AUTOSAR XML (schema 4-0-3)
package /MICROSAR_SWCS_DEV/NvM_swc/ComponentTypes
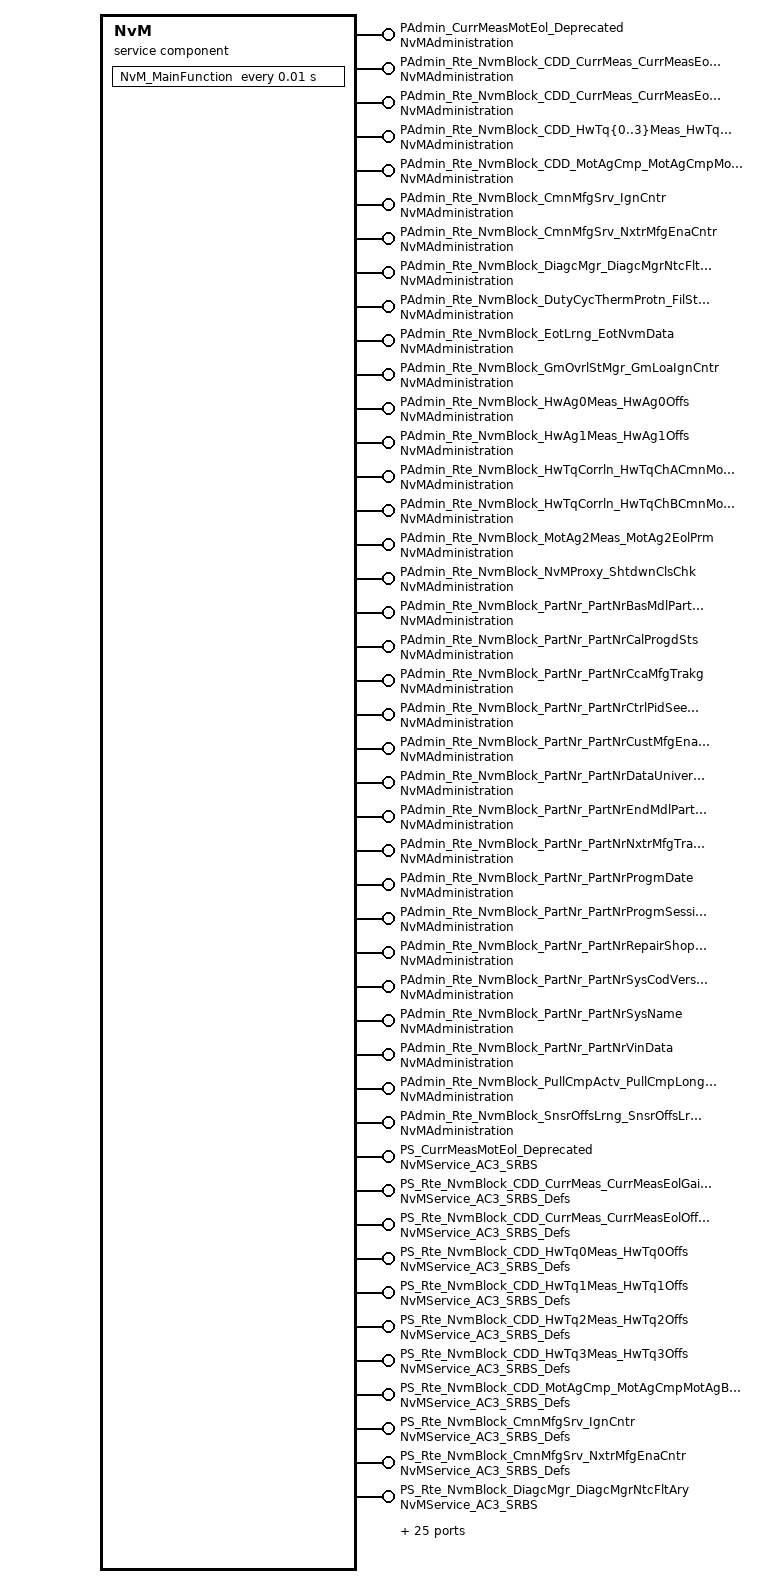
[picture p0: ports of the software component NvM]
  service sw component type NvM
    72 x provide port:
      PAdmin_CurrMeasMotEol_Deprecated: server-com-spec{operation=SetBlockProtection, queue-length=1}, provided-interface=NvMAdministration
      PAdmin_Rte_NvmBlock_CDD_CurrMeas_CurrMeasEolGainCalSet: server-com-spec{operation=SetBlockProtection, queue-length=1}, provided-interface=NvMAdministration
      PAdmin_Rte_NvmBlock_CDD_CurrMeas_CurrMeasEolOffsCalSet: server-com-spec{operation=SetBlockProtection, queue-length=1}, provided-interface=NvMAdministration
      PAdmin_Rte_NvmBlock_CDD_HwTq{0..3}Meas_HwTq{0..3}Offs: server-com-spec{operation=SetBlockProtection, queue-length=1}, provided-interface=NvMAdministration
      PAdmin_Rte_NvmBlock_CDD_MotAgCmp_MotAgCmpMotAgBackEmf: server-com-spec{operation=SetBlockProtection, queue-length=1}, provided-interface=NvMAdministration
      PAdmin_Rte_NvmBlock_CmnMfgSrv_IgnCntr: server-com-spec{operation=SetBlockProtection, queue-length=1}, provided-interface=NvMAdministration
      PAdmin_Rte_NvmBlock_CmnMfgSrv_NxtrMfgEnaCntr: server-com-spec{operation=SetBlockProtection, queue-length=1}, provided-interface=NvMAdministration
      PAdmin_Rte_NvmBlock_DiagcMgr_DiagcMgrNtcFltAry: server-com-spec{operation=SetBlockProtection, queue-length=1}, provided-interface=NvMAdministration
      PAdmin_Rte_NvmBlock_DutyCycThermProtn_FilStVal: server-com-spec{operation=SetBlockProtection, queue-length=1}, provided-interface=NvMAdministration
      PAdmin_Rte_NvmBlock_EotLrng_EotNvmData: server-com-spec{operation=SetBlockProtection, queue-length=1}, provided-interface=NvMAdministration
      PAdmin_Rte_NvmBlock_GmOvrlStMgr_GmLoaIgnCntr: server-com-spec{operation=SetBlockProtection, queue-length=1}, provided-interface=NvMAdministration
      PAdmin_Rte_NvmBlock_HwAg0Meas_HwAg0Offs: server-com-spec{operation=SetBlockProtection, queue-length=1}, provided-interface=NvMAdministration
      PAdmin_Rte_NvmBlock_HwAg1Meas_HwAg1Offs: server-com-spec{operation=SetBlockProtection, queue-length=1}, provided-interface=NvMAdministration
      PAdmin_Rte_NvmBlock_HwTqCorrln_HwTqChACmnModCmpLpFilSt: server-com-spec{operation=SetBlockProtection, queue-length=1}, provided-interface=NvMAdministration
      PAdmin_Rte_NvmBlock_HwTqCorrln_HwTqChBCmnModCmpLpFilSt: server-com-spec{operation=SetBlockProtection, queue-length=1}, provided-interface=NvMAdministration
      PAdmin_Rte_NvmBlock_MotAg2Meas_MotAg2EolPrm: server-com-spec{operation=SetBlockProtection, queue-length=1}, provided-interface=NvMAdministration
      PAdmin_Rte_NvmBlock_NvMProxy_ShtdwnClsChk: server-com-spec{operation=SetBlockProtection, queue-length=1}, provided-interface=NvMAdministration
      PAdmin_Rte_NvmBlock_PartNr_PartNrBasMdlPartNr: server-com-spec{operation=SetBlockProtection, queue-length=1}, provided-interface=NvMAdministration
      PAdmin_Rte_NvmBlock_PartNr_PartNrCalProgdSts: server-com-spec{operation=SetBlockProtection, queue-length=1}, provided-interface=NvMAdministration
      PAdmin_Rte_NvmBlock_PartNr_PartNrCcaMfgTrakg: server-com-spec{operation=SetBlockProtection, queue-length=1}, provided-interface=NvMAdministration
      PAdmin_Rte_NvmBlock_PartNr_PartNrCtrlPidSeedKey: server-com-spec{operation=SetBlockProtection, queue-length=1}, provided-interface=NvMAdministration
      PAdmin_Rte_NvmBlock_PartNr_PartNrCustMfgEnaCntr: server-com-spec{operation=SetBlockProtection, queue-length=1}, provided-interface=NvMAdministration
      PAdmin_Rte_NvmBlock_PartNr_PartNrDataUniversalNrSysId: server-com-spec{operation=SetBlockProtection, queue-length=1}, provided-interface=NvMAdministration
      PAdmin_Rte_NvmBlock_PartNr_PartNrEndMdlPartNr: server-com-spec{operation=SetBlockProtection, queue-length=1}, provided-interface=NvMAdministration
      PAdmin_Rte_NvmBlock_PartNr_PartNrNxtrMfgTrakg: server-com-spec{operation=SetBlockProtection, queue-length=1}, provided-interface=NvMAdministration
      PAdmin_Rte_NvmBlock_PartNr_PartNrProgmDate: server-com-spec{operation=SetBlockProtection, queue-length=1}, provided-interface=NvMAdministration
      PAdmin_Rte_NvmBlock_PartNr_PartNrProgmSessionSeedKey: server-com-spec{operation=SetBlockProtection, queue-length=1}, provided-interface=NvMAdministration
      PAdmin_Rte_NvmBlock_PartNr_PartNrRepairShopCod: server-com-spec{operation=SetBlockProtection, queue-length=1}, provided-interface=NvMAdministration
      PAdmin_Rte_NvmBlock_PartNr_PartNrSysCodVersNr: server-com-spec{operation=SetBlockProtection, queue-length=1}, provided-interface=NvMAdministration
      PAdmin_Rte_NvmBlock_PartNr_PartNrSysName: server-com-spec{operation=SetBlockProtection, queue-length=1}, provided-interface=NvMAdministration
      PAdmin_Rte_NvmBlock_PartNr_PartNrVinData: server-com-spec{operation=SetBlockProtection, queue-length=1}, provided-interface=NvMAdministration
      PAdmin_Rte_NvmBlock_PullCmpActv_PullCmpLongTerm: server-com-spec{operation=SetBlockProtection, queue-length=1}, provided-interface=NvMAdministration
      PAdmin_Rte_NvmBlock_SnsrOffsLrng_SnsrOffsLrnd: server-com-spec{operation=SetBlockProtection, queue-length=1}, provided-interface=NvMAdministration
      PS_CurrMeasMotEol_Deprecated: provided-interface=NvMService_AC3_SRBS
        provided-com-specs:
          operation=EraseBlock, queue-length=1
          operation=GetErrorStatus, queue-length=1
          operation=InvalidateNvBlock, queue-length=1
          operation=ReadBlock, queue-length=1
          operation=SetRamBlockStatus, queue-length=1
          operation=WriteBlock, queue-length=1
      PS_Rte_NvmBlock_CDD_CurrMeas_CurrMeasEolGainCalSet: provided-interface=NvMService_AC3_SRBS_Defs
        provided-com-specs:
          operation=EraseBlock, queue-length=1
          operation=GetErrorStatus, queue-length=1
          operation=InvalidateNvBlock, queue-length=1
          operation=ReadBlock, queue-length=1
          operation=RestoreBlockDefaults, queue-length=1
          operation=SetRamBlockStatus, queue-length=1
          operation=WriteBlock, queue-length=1
      PS_Rte_NvmBlock_CDD_CurrMeas_CurrMeasEolOffsCalSet: provided-interface=NvMService_AC3_SRBS_Defs
        provided-com-specs:
          operation=EraseBlock, queue-length=1
          operation=GetErrorStatus, queue-length=1
          operation=InvalidateNvBlock, queue-length=1
          operation=ReadBlock, queue-length=1
          operation=RestoreBlockDefaults, queue-length=1
          operation=SetRamBlockStatus, queue-length=1
          operation=WriteBlock, queue-length=1
      PS_Rte_NvmBlock_CDD_HwTq0Meas_HwTq0Offs: provided-interface=NvMService_AC3_SRBS_Defs
        provided-com-specs:
          operation=EraseBlock, queue-length=1
          operation=GetErrorStatus, queue-length=1
          operation=InvalidateNvBlock, queue-length=1
          operation=ReadBlock, queue-length=1
          operation=RestoreBlockDefaults, queue-length=1
          operation=SetRamBlockStatus, queue-length=1
          operation=WriteBlock, queue-length=1
      PS_Rte_NvmBlock_CDD_HwTq1Meas_HwTq1Offs: provided-interface=NvMService_AC3_SRBS_Defs
        provided-com-specs:
          operation=EraseBlock, queue-length=1
          operation=GetErrorStatus, queue-length=1
          operation=InvalidateNvBlock, queue-length=1
          operation=ReadBlock, queue-length=1
          operation=RestoreBlockDefaults, queue-length=1
          operation=SetRamBlockStatus, queue-length=1
          operation=WriteBlock, queue-length=1
      PS_Rte_NvmBlock_CDD_HwTq2Meas_HwTq2Offs: provided-interface=NvMService_AC3_SRBS_Defs
        provided-com-specs:
          operation=EraseBlock, queue-length=1
          operation=GetErrorStatus, queue-length=1
          operation=InvalidateNvBlock, queue-length=1
          operation=ReadBlock, queue-length=1
          operation=RestoreBlockDefaults, queue-length=1
          operation=SetRamBlockStatus, queue-length=1
          operation=WriteBlock, queue-length=1
      PS_Rte_NvmBlock_CDD_HwTq3Meas_HwTq3Offs: provided-interface=NvMService_AC3_SRBS_Defs
        provided-com-specs:
          operation=EraseBlock, queue-length=1
          operation=GetErrorStatus, queue-length=1
          operation=InvalidateNvBlock, queue-length=1
          operation=ReadBlock, queue-length=1
          operation=RestoreBlockDefaults, queue-length=1
          operation=SetRamBlockStatus, queue-length=1
          operation=WriteBlock, queue-length=1
      PS_Rte_NvmBlock_CDD_MotAgCmp_MotAgCmpMotAgBackEmf: provided-interface=NvMService_AC3_SRBS_Defs
        provided-com-specs:
          operation=EraseBlock, queue-length=1
          operation=GetErrorStatus, queue-length=1
          operation=InvalidateNvBlock, queue-length=1
          operation=ReadBlock, queue-length=1
          operation=RestoreBlockDefaults, queue-length=1
          operation=SetRamBlockStatus, queue-length=1
          operation=WriteBlock, queue-length=1
      PS_Rte_NvmBlock_CmnMfgSrv_IgnCntr: provided-interface=NvMService_AC3_SRBS_Defs
        provided-com-specs:
          operation=EraseBlock, queue-length=1
          operation=GetErrorStatus, queue-length=1
          operation=InvalidateNvBlock, queue-length=1
          operation=ReadBlock, queue-length=1
          operation=RestoreBlockDefaults, queue-length=1
          operation=SetRamBlockStatus, queue-length=1
          operation=WriteBlock, queue-length=1
      PS_Rte_NvmBlock_CmnMfgSrv_NxtrMfgEnaCntr: provided-interface=NvMService_AC3_SRBS_Defs
        provided-com-specs:
          operation=EraseBlock, queue-length=1
          operation=GetErrorStatus, queue-length=1
          operation=InvalidateNvBlock, queue-length=1
          operation=ReadBlock, queue-length=1
          operation=RestoreBlockDefaults, queue-length=1
          operation=SetRamBlockStatus, queue-length=1
          operation=WriteBlock, queue-length=1
      PS_Rte_NvmBlock_DiagcMgr_DiagcMgrNtcFltAry: provided-interface=NvMService_AC3_SRBS
        provided-com-specs:
          operation=EraseBlock, queue-length=1
          operation=GetErrorStatus, queue-length=1
          operation=InvalidateNvBlock, queue-length=1
          operation=ReadBlock, queue-length=1
          operation=SetRamBlockStatus, queue-length=1
          operation=WriteBlock, queue-length=1
      PS_Rte_NvmBlock_DutyCycThermProtn_FilStVal: provided-interface=NvMService_AC3_SRBS_Defs
        provided-com-specs:
          operation=EraseBlock, queue-length=1
          operation=GetErrorStatus, queue-length=1
          operation=InvalidateNvBlock, queue-length=1
          operation=ReadBlock, queue-length=1
          operation=RestoreBlockDefaults, queue-length=1
          operation=SetRamBlockStatus, queue-length=1
          operation=WriteBlock, queue-length=1
      PS_Rte_NvmBlock_EotLrng_EotNvmData: provided-interface=NvMService_AC3_SRBS_Defs
        provided-com-specs:
          operation=EraseBlock, queue-length=1
          operation=GetErrorStatus, queue-length=1
          operation=InvalidateNvBlock, queue-length=1
          operation=ReadBlock, queue-length=1
          operation=RestoreBlockDefaults, queue-length=1
          operation=SetRamBlockStatus, queue-length=1
          operation=WriteBlock, queue-length=1
      PS_Rte_NvmBlock_GmOvrlStMgr_GmLoaIgnCntr: provided-interface=NvMService_AC3_SRBS
        provided-com-specs:
          operation=EraseBlock, queue-length=1
          operation=GetErrorStatus, queue-length=1
          operation=InvalidateNvBlock, queue-length=1
          operation=ReadBlock, queue-length=1
          operation=SetRamBlockStatus, queue-length=1
          operation=WriteBlock, queue-length=1
      PS_Rte_NvmBlock_HwAg0Meas_HwAg0Offs: provided-interface=NvMService_AC3_SRBS_Defs
        provided-com-specs:
          operation=EraseBlock, queue-length=1
          operation=GetErrorStatus, queue-length=1
          operation=InvalidateNvBlock, queue-length=1
          operation=ReadBlock, queue-length=1
          operation=RestoreBlockDefaults, queue-length=1
          operation=SetRamBlockStatus, queue-length=1
          operation=WriteBlock, queue-length=1
      PS_Rte_NvmBlock_HwAg1Meas_HwAg1Offs: provided-interface=NvMService_AC3_SRBS_Defs
        provided-com-specs:
          operation=EraseBlock, queue-length=1
          operation=GetErrorStatus, queue-length=1
          operation=InvalidateNvBlock, queue-length=1
          operation=ReadBlock, queue-length=1
          operation=RestoreBlockDefaults, queue-length=1
          operation=SetRamBlockStatus, queue-length=1
          operation=WriteBlock, queue-length=1
      PS_Rte_NvmBlock_HwTqCorrln_HwTqChACmnModCmpLpFilSt: provided-interface=NvMService_AC3_SRBS_Defs
        provided-com-specs:
          operation=EraseBlock, queue-length=1
          operation=GetErrorStatus, queue-length=1
          operation=InvalidateNvBlock, queue-length=1
          operation=ReadBlock, queue-length=1
          operation=RestoreBlockDefaults, queue-length=1
          operation=SetRamBlockStatus, queue-length=1
          operation=WriteBlock, queue-length=1
      PS_Rte_NvmBlock_HwTqCorrln_HwTqChBCmnModCmpLpFilSt: provided-interface=NvMService_AC3_SRBS_Defs
        provided-com-specs:
          operation=EraseBlock, queue-length=1
          operation=GetErrorStatus, queue-length=1
          operation=InvalidateNvBlock, queue-length=1
          operation=ReadBlock, queue-length=1
          operation=RestoreBlockDefaults, queue-length=1
          operation=SetRamBlockStatus, queue-length=1
          operation=WriteBlock, queue-length=1
      PS_Rte_NvmBlock_MotAg2Meas_MotAg2EolPrm: provided-interface=NvMService_AC3_SRBS_Defs
        provided-com-specs:
          operation=EraseBlock, queue-length=1
          operation=GetErrorStatus, queue-length=1
          operation=InvalidateNvBlock, queue-length=1
          operation=ReadBlock, queue-length=1
          operation=RestoreBlockDefaults, queue-length=1
          operation=SetRamBlockStatus, queue-length=1
          operation=WriteBlock, queue-length=1
      PS_Rte_NvmBlock_NvMProxy_ShtdwnClsChk: provided-interface=NvMService_AC3_SRBS
        provided-com-specs:
          operation=EraseBlock, queue-length=1
          operation=GetErrorStatus, queue-length=1
          operation=InvalidateNvBlock, queue-length=1
          operation=ReadBlock, queue-length=1
          operation=SetRamBlockStatus, queue-length=1
          operation=WriteBlock, queue-length=1
      PS_Rte_NvmBlock_PartNr_PartNrBasMdlPartNr: provided-interface=NvMService_AC3_SRBS_Defs
        provided-com-specs:
          operation=EraseBlock, queue-length=1
          operation=GetErrorStatus, queue-length=1
          operation=InvalidateNvBlock, queue-length=1
          operation=ReadBlock, queue-length=1
          operation=RestoreBlockDefaults, queue-length=1
          operation=SetRamBlockStatus, queue-length=1
          operation=WriteBlock, queue-length=1
      PS_Rte_NvmBlock_PartNr_PartNrCalProgdSts: provided-interface=NvMService_AC3_SRBS_Defs
        provided-com-specs:
          operation=EraseBlock, queue-length=1
          operation=GetErrorStatus, queue-length=1
          operation=InvalidateNvBlock, queue-length=1
          operation=ReadBlock, queue-length=1
          operation=RestoreBlockDefaults, queue-length=1
          operation=SetRamBlockStatus, queue-length=1
          operation=WriteBlock, queue-length=1
      PS_Rte_NvmBlock_PartNr_PartNrCcaMfgTrakg: provided-interface=NvMService_AC3_SRBS_Defs
        provided-com-specs:
          operation=EraseBlock, queue-length=1
          operation=GetErrorStatus, queue-length=1
          operation=InvalidateNvBlock, queue-length=1
          operation=ReadBlock, queue-length=1
          operation=RestoreBlockDefaults, queue-length=1
          operation=SetRamBlockStatus, queue-length=1
          operation=WriteBlock, queue-length=1
      PS_Rte_NvmBlock_PartNr_PartNrCtrlPidSeedKey: provided-interface=NvMService_AC3_SRBS_Defs
        provided-com-specs:
          operation=EraseBlock, queue-length=1
          operation=GetErrorStatus, queue-length=1
          operation=InvalidateNvBlock, queue-length=1
          operation=ReadBlock, queue-length=1
          operation=RestoreBlockDefaults, queue-length=1
          operation=SetRamBlockStatus, queue-length=1
          operation=WriteBlock, queue-length=1
      PS_Rte_NvmBlock_PartNr_PartNrCustMfgEnaCntr: provided-interface=NvMService_AC3_SRBS_Defs
        provided-com-specs:
          operation=EraseBlock, queue-length=1
          operation=GetErrorStatus, queue-length=1
          operation=InvalidateNvBlock, queue-length=1
          operation=ReadBlock, queue-length=1
          operation=RestoreBlockDefaults, queue-length=1
          operation=SetRamBlockStatus, queue-length=1
          operation=WriteBlock, queue-length=1
      PS_Rte_NvmBlock_PartNr_PartNrDataUniversalNrSysId: provided-interface=NvMService_AC3_SRBS_Defs
        provided-com-specs:
          operation=EraseBlock, queue-length=1
          operation=GetErrorStatus, queue-length=1
          operation=InvalidateNvBlock, queue-length=1
          operation=ReadBlock, queue-length=1
          operation=RestoreBlockDefaults, queue-length=1
          operation=SetRamBlockStatus, queue-length=1
          operation=WriteBlock, queue-length=1
      PS_Rte_NvmBlock_PartNr_PartNrEndMdlPartNr: provided-interface=NvMService_AC3_SRBS_Defs
        provided-com-specs:
          operation=EraseBlock, queue-length=1
          operation=GetErrorStatus, queue-length=1
          operation=InvalidateNvBlock, queue-length=1
          operation=ReadBlock, queue-length=1
          operation=RestoreBlockDefaults, queue-length=1
          operation=SetRamBlockStatus, queue-length=1
          operation=WriteBlock, queue-length=1
      PS_Rte_NvmBlock_PartNr_PartNrNxtrMfgTrakg: provided-interface=NvMService_AC3_SRBS_Defs
        provided-com-specs:
          operation=EraseBlock, queue-length=1
          operation=GetErrorStatus, queue-length=1
          operation=InvalidateNvBlock, queue-length=1
          operation=ReadBlock, queue-length=1
          operation=RestoreBlockDefaults, queue-length=1
          operation=SetRamBlockStatus, queue-length=1
          operation=WriteBlock, queue-length=1
      PS_Rte_NvmBlock_PartNr_PartNrProgmDate: provided-interface=NvMService_AC3_SRBS_Defs
        provided-com-specs:
          operation=EraseBlock, queue-length=1
          operation=GetErrorStatus, queue-length=1
          operation=InvalidateNvBlock, queue-length=1
          operation=ReadBlock, queue-length=1
          operation=RestoreBlockDefaults, queue-length=1
          operation=SetRamBlockStatus, queue-length=1
          operation=WriteBlock, queue-length=1
      PS_Rte_NvmBlock_PartNr_PartNrProgmSessionSeedKey: provided-interface=NvMService_AC3_SRBS_Defs
        provided-com-specs:
          operation=EraseBlock, queue-length=1
          operation=GetErrorStatus, queue-length=1
          operation=InvalidateNvBlock, queue-length=1
          operation=ReadBlock, queue-length=1
          operation=RestoreBlockDefaults, queue-length=1
          operation=SetRamBlockStatus, queue-length=1
          operation=WriteBlock, queue-length=1
      PS_Rte_NvmBlock_PartNr_PartNrRepairShopCod: provided-interface=NvMService_AC3_SRBS_Defs
        provided-com-specs:
          operation=EraseBlock, queue-length=1
          operation=GetErrorStatus, queue-length=1
          operation=InvalidateNvBlock, queue-length=1
          operation=ReadBlock, queue-length=1
          operation=RestoreBlockDefaults, queue-length=1
          operation=SetRamBlockStatus, queue-length=1
          operation=WriteBlock, queue-length=1
      PS_Rte_NvmBlock_PartNr_PartNrSysCodVersNr: provided-interface=NvMService_AC3_SRBS_Defs
        provided-com-specs:
          operation=EraseBlock, queue-length=1
          operation=GetErrorStatus, queue-length=1
          operation=InvalidateNvBlock, queue-length=1
          operation=ReadBlock, queue-length=1
          operation=RestoreBlockDefaults, queue-length=1
          operation=SetRamBlockStatus, queue-length=1
          operation=WriteBlock, queue-length=1
      PS_Rte_NvmBlock_PartNr_PartNrSysName: provided-interface=NvMService_AC3_SRBS_Defs
        provided-com-specs:
          operation=EraseBlock, queue-length=1
          operation=GetErrorStatus, queue-length=1
          operation=InvalidateNvBlock, queue-length=1
          operation=ReadBlock, queue-length=1
          operation=RestoreBlockDefaults, queue-length=1
          operation=SetRamBlockStatus, queue-length=1
          operation=WriteBlock, queue-length=1
      PS_Rte_NvmBlock_PartNr_PartNrVinData: provided-interface=NvMService_AC3_SRBS_Defs
        provided-com-specs:
          operation=EraseBlock, queue-length=1
          operation=GetErrorStatus, queue-length=1
          operation=InvalidateNvBlock, queue-length=1
          operation=ReadBlock, queue-length=1
          operation=RestoreBlockDefaults, queue-length=1
          operation=SetRamBlockStatus, queue-length=1
          operation=WriteBlock, queue-length=1
      PS_Rte_NvmBlock_PullCmpActv_PullCmpLongTerm: provided-interface=NvMService_AC3_SRBS_Defs
        provided-com-specs:
          operation=EraseBlock, queue-length=1
          operation=GetErrorStatus, queue-length=1
          operation=InvalidateNvBlock, queue-length=1
          operation=ReadBlock, queue-length=1
          operation=RestoreBlockDefaults, queue-length=1
          operation=SetRamBlockStatus, queue-length=1
          operation=WriteBlock, queue-length=1
      PS_Rte_NvmBlock_SnsrOffsLrng_SnsrOffsLrnd: provided-interface=NvMService_AC3_SRBS
        provided-com-specs:
          operation=EraseBlock, queue-length=1
          operation=GetErrorStatus, queue-length=1
          operation=InvalidateNvBlock, queue-length=1
          operation=ReadBlock, queue-length=1
          operation=SetRamBlockStatus, queue-length=1
          operation=WriteBlock, queue-length=1
    behavior NvMInternalBehavior
      108 x operation invoked event:
        OpEventEraseBlock_EraseBlock_PS_CurrMeasMotEol_Deprecated: start-on-event=EraseBlock, operation=PS_CurrMeasMotEol_Deprecated.EraseBlock
        OpEventEraseBlock_EraseBlock_PS_Rte_NvmBlock_CDD_CurrMeas_CurrMeasEolGainCalSet: start-on-event=EraseBlock, operation=PS_Rte_NvmBlock_CDD_CurrMeas_CurrMeasEolGainCalSet.EraseBlock
        OpEventEraseBlock_EraseBlock_PS_Rte_NvmBlock_CDD_CurrMeas_CurrMeasEolOffsCalSet: start-on-event=EraseBlock, operation=PS_Rte_NvmBlock_CDD_CurrMeas_CurrMeasEolOffsCalSet.EraseBlock
        OpEventEraseBlock_EraseBlock_PS_Rte_NvmBlock_CDD_HwTq{0..3}Meas_HwTq{0..3}Offs: start-on-event=EraseBlock, operation=PS_Rte_NvmBlock_CDD_HwTq{0..3}Meas_HwTq{0..3}Offs.EraseBlock
        OpEventEraseBlock_EraseBlock_PS_Rte_NvmBlock_CDD_MotAgCmp_MotAgCmpMotAgBackEmf: start-on-event=EraseBlock, operation=PS_Rte_NvmBlock_CDD_MotAgCmp_MotAgCmpMotAgBackEmf.EraseBlock
        OpEventEraseBlock_EraseBlock_PS_Rte_NvmBlock_CmnMfgSrv_IgnCntr: start-on-event=EraseBlock, operation=PS_Rte_NvmBlock_CmnMfgSrv_IgnCntr.EraseBlock
        OpEventEraseBlock_EraseBlock_PS_Rte_NvmBlock_CmnMfgSrv_NxtrMfgEnaCntr: start-on-event=EraseBlock, operation=PS_Rte_NvmBlock_CmnMfgSrv_NxtrMfgEnaCntr.EraseBlock
        OpEventEraseBlock_EraseBlock_PS_Rte_NvmBlock_DiagcMgr_DiagcMgrNtcFltAry: start-on-event=EraseBlock, operation=PS_Rte_NvmBlock_DiagcMgr_DiagcMgrNtcFltAry.EraseBlock
        OpEventEraseBlock_EraseBlock_PS_Rte_NvmBlock_DutyCycThermProtn_FilStVal: start-on-event=EraseBlock, operation=PS_Rte_NvmBlock_DutyCycThermProtn_FilStVal.EraseBlock
        OpEventEraseBlock_EraseBlock_PS_Rte_NvmBlock_EotLrng_EotNvmData: start-on-event=EraseBlock, operation=PS_Rte_NvmBlock_EotLrng_EotNvmData.EraseBlock
        OpEventEraseBlock_EraseBlock_PS_Rte_NvmBlock_GmOvrlStMgr_GmLoaIgnCntr: start-on-event=EraseBlock, operation=PS_Rte_NvmBlock_GmOvrlStMgr_GmLoaIgnCntr.EraseBlock
        OpEventEraseBlock_EraseBlock_PS_Rte_NvmBlock_HwAg0Meas_HwAg0Offs: start-on-event=EraseBlock, operation=PS_Rte_NvmBlock_HwAg0Meas_HwAg0Offs.EraseBlock
        OpEventEraseBlock_EraseBlock_PS_Rte_NvmBlock_HwAg1Meas_HwAg1Offs: start-on-event=EraseBlock, operation=PS_Rte_NvmBlock_HwAg1Meas_HwAg1Offs.EraseBlock
        OpEventEraseBlock_EraseBlock_PS_Rte_NvmBlock_HwTqCorrln_HwTqChACmnModCmpLpFilSt: start-on-event=EraseBlock, operation=PS_Rte_NvmBlock_HwTqCorrln_HwTqChACmnModCmpLpFilSt.EraseBlock
        OpEventEraseBlock_EraseBlock_PS_Rte_NvmBlock_HwTqCorrln_HwTqChBCmnModCmpLpFilSt: start-on-event=EraseBlock, operation=PS_Rte_NvmBlock_HwTqCorrln_HwTqChBCmnModCmpLpFilSt.EraseBlock
        OpEventEraseBlock_EraseBlock_PS_Rte_NvmBlock_MotAg2Meas_MotAg2EolPrm: start-on-event=EraseBlock, operation=PS_Rte_NvmBlock_MotAg2Meas_MotAg2EolPrm.EraseBlock
        OpEventEraseBlock_EraseBlock_PS_Rte_NvmBlock_NvMProxy_ShtdwnClsChk: start-on-event=EraseBlock, operation=PS_Rte_NvmBlock_NvMProxy_ShtdwnClsChk.EraseBlock
        OpEventEraseBlock_EraseBlock_PS_Rte_NvmBlock_PartNr_PartNrBasMdlPartNr: start-on-event=EraseBlock, operation=PS_Rte_NvmBlock_PartNr_PartNrBasMdlPartNr.EraseBlock
        OpEventEraseBlock_EraseBlock_PS_Rte_NvmBlock_PartNr_PartNrCalProgdSts: start-on-event=EraseBlock, operation=PS_Rte_NvmBlock_PartNr_PartNrCalProgdSts.EraseBlock
        OpEventEraseBlock_EraseBlock_PS_Rte_NvmBlock_PartNr_PartNrCcaMfgTrakg: start-on-event=EraseBlock, operation=PS_Rte_NvmBlock_PartNr_PartNrCcaMfgTrakg.EraseBlock
        OpEventEraseBlock_EraseBlock_PS_Rte_NvmBlock_PartNr_PartNrCtrlPidSeedKey: start-on-event=EraseBlock, operation=PS_Rte_NvmBlock_PartNr_PartNrCtrlPidSeedKey.EraseBlock
        OpEventEraseBlock_EraseBlock_PS_Rte_NvmBlock_PartNr_PartNrCustMfgEnaCntr: start-on-event=EraseBlock, operation=PS_Rte_NvmBlock_PartNr_PartNrCustMfgEnaCntr.EraseBlock
        OpEventEraseBlock_EraseBlock_PS_Rte_NvmBlock_PartNr_PartNrDataUniversalNrSysId: start-on-event=EraseBlock, operation=PS_Rte_NvmBlock_PartNr_PartNrDataUniversalNrSysId.EraseBlock
        OpEventEraseBlock_EraseBlock_PS_Rte_NvmBlock_PartNr_PartNrEndMdlPartNr: start-on-event=EraseBlock, operation=PS_Rte_NvmBlock_PartNr_PartNrEndMdlPartNr.EraseBlock
        OpEventEraseBlock_EraseBlock_PS_Rte_NvmBlock_PartNr_PartNrNxtrMfgTrakg: start-on-event=EraseBlock, operation=PS_Rte_NvmBlock_PartNr_PartNrNxtrMfgTrakg.EraseBlock
        OpEventEraseBlock_EraseBlock_PS_Rte_NvmBlock_PartNr_PartNrProgmDate: start-on-event=EraseBlock, operation=PS_Rte_NvmBlock_PartNr_PartNrProgmDate.EraseBlock
        OpEventEraseBlock_EraseBlock_PS_Rte_NvmBlock_PartNr_PartNrProgmSessionSeedKey: start-on-event=EraseBlock, operation=PS_Rte_NvmBlock_PartNr_PartNrProgmSessionSeedKey.EraseBlock
        OpEventEraseBlock_EraseBlock_PS_Rte_NvmBlock_PartNr_PartNrRepairShopCod: start-on-event=EraseBlock, operation=PS_Rte_NvmBlock_PartNr_PartNrRepairShopCod.EraseBlock
        OpEventEraseBlock_EraseBlock_PS_Rte_NvmBlock_PartNr_PartNrSysCodVersNr: start-on-event=EraseBlock, operation=PS_Rte_NvmBlock_PartNr_PartNrSysCodVersNr.EraseBlock
        OpEventEraseBlock_EraseBlock_PS_Rte_NvmBlock_PartNr_PartNrSysName: start-on-event=EraseBlock, operation=PS_Rte_NvmBlock_PartNr_PartNrSysName.EraseBlock
        OpEventEraseBlock_EraseBlock_PS_Rte_NvmBlock_PartNr_PartNrVinData: start-on-event=EraseBlock, operation=PS_Rte_NvmBlock_PartNr_PartNrVinData.EraseBlock
        OpEventEraseBlock_EraseBlock_PS_Rte_NvmBlock_PullCmpActv_PullCmpLongTerm: start-on-event=EraseBlock, operation=PS_Rte_NvmBlock_PullCmpActv_PullCmpLongTerm.EraseBlock
        OpEventEraseBlock_EraseBlock_PS_Rte_NvmBlock_SnsrOffsLrng_SnsrOffsLrnd: start-on-event=EraseBlock, operation=PS_Rte_NvmBlock_SnsrOffsLrng_SnsrOffsLrnd.EraseBlock
        OpEventGetErrorStatus_GetErrorStatus_PS_CurrMeasMotEol_Deprecated: start-on-event=GetErrorStatus, operation=PS_CurrMeasMotEol_Deprecated.GetErrorStatus
        OpEventGetErrorStatus_GetErrorStatus_PS_Rte_NvmBlock_CDD_CurrMeas_CurrMeasEolGainCalSet: start-on-event=GetErrorStatus, operation=PS_Rte_NvmBlock_CDD_CurrMeas_CurrMeasEolGainCalSet.GetErrorStatus
        OpEventGetErrorStatus_GetErrorStatus_PS_Rte_NvmBlock_CDD_CurrMeas_CurrMeasEolOffsCalSet: start-on-event=GetErrorStatus, operation=PS_Rte_NvmBlock_CDD_CurrMeas_CurrMeasEolOffsCalSet.GetErrorStatus
        OpEventGetErrorStatus_GetErrorStatus_PS_Rte_NvmBlock_CDD_HwTq{0..3}Meas_HwTq{0..3}Offs: start-on-event=GetErrorStatus, operation=PS_Rte_NvmBlock_CDD_HwTq{0..3}Meas_HwTq{0..3}Offs.GetErrorStatus
        OpEventGetErrorStatus_GetErrorStatus_PS_Rte_NvmBlock_CDD_MotAgCmp_MotAgCmpMotAgBackEmf: start-on-event=GetErrorStatus, operation=PS_Rte_NvmBlock_CDD_MotAgCmp_MotAgCmpMotAgBackEmf.GetErrorStatus
        OpEventGetErrorStatus_GetErrorStatus_PS_Rte_NvmBlock_CmnMfgSrv_IgnCntr: start-on-event=GetErrorStatus, operation=PS_Rte_NvmBlock_CmnMfgSrv_IgnCntr.GetErrorStatus
        OpEventGetErrorStatus_GetErrorStatus_PS_Rte_NvmBlock_CmnMfgSrv_NxtrMfgEnaCntr: start-on-event=GetErrorStatus, operation=PS_Rte_NvmBlock_CmnMfgSrv_NxtrMfgEnaCntr.GetErrorStatus
        OpEventGetErrorStatus_GetErrorStatus_PS_Rte_NvmBlock_DiagcMgr_DiagcMgrNtcFltAry: start-on-event=GetErrorStatus, operation=PS_Rte_NvmBlock_DiagcMgr_DiagcMgrNtcFltAry.GetErrorStatus
        OpEventGetErrorStatus_GetErrorStatus_PS_Rte_NvmBlock_DutyCycThermProtn_FilStVal: start-on-event=GetErrorStatus, operation=PS_Rte_NvmBlock_DutyCycThermProtn_FilStVal.GetErrorStatus
        OpEventGetErrorStatus_GetErrorStatus_PS_Rte_NvmBlock_EotLrng_EotNvmData: start-on-event=GetErrorStatus, operation=PS_Rte_NvmBlock_EotLrng_EotNvmData.GetErrorStatus
        OpEventGetErrorStatus_GetErrorStatus_PS_Rte_NvmBlock_GmOvrlStMgr_GmLoaIgnCntr: start-on-event=GetErrorStatus, operation=PS_Rte_NvmBlock_GmOvrlStMgr_GmLoaIgnCntr.GetErrorStatus
        OpEventGetErrorStatus_GetErrorStatus_PS_Rte_NvmBlock_HwAg0Meas_HwAg0Offs: start-on-event=GetErrorStatus, operation=PS_Rte_NvmBlock_HwAg0Meas_HwAg0Offs.GetErrorStatus
        OpEventGetErrorStatus_GetErrorStatus_PS_Rte_NvmBlock_HwAg1Meas_HwAg1Offs: start-on-event=GetErrorStatus, operation=PS_Rte_NvmBlock_HwAg1Meas_HwAg1Offs.GetErrorStatus
        OpEventGetErrorStatus_GetErrorStatus_PS_Rte_NvmBlock_HwTqCorrln_HwTqChACmnModCmpLpFilSt: start-on-event=GetErrorStatus, operation=PS_Rte_NvmBlock_HwTqCorrln_HwTqChACmnModCmpLpFilSt.GetErrorStatus
        OpEventGetErrorStatus_GetErrorStatus_PS_Rte_NvmBlock_HwTqCorrln_HwTqChBCmnModCmpLpFilSt: start-on-event=GetErrorStatus, operation=PS_Rte_NvmBlock_HwTqCorrln_HwTqChBCmnModCmpLpFilSt.GetErrorStatus
        OpEventGetErrorStatus_GetErrorStatus_PS_Rte_NvmBlock_MotAg2Meas_MotAg2EolPrm: start-on-event=GetErrorStatus, operation=PS_Rte_NvmBlock_MotAg2Meas_MotAg2EolPrm.GetErrorStatus
        OpEventGetErrorStatus_GetErrorStatus_PS_Rte_NvmBlock_NvMProxy_ShtdwnClsChk: start-on-event=GetErrorStatus, operation=PS_Rte_NvmBlock_NvMProxy_ShtdwnClsChk.GetErrorStatus
        OpEventGetErrorStatus_GetErrorStatus_PS_Rte_NvmBlock_PartNr_PartNrBasMdlPartNr: start-on-event=GetErrorStatus, operation=PS_Rte_NvmBlock_PartNr_PartNrBasMdlPartNr.GetErrorStatus
        OpEventGetErrorStatus_GetErrorStatus_PS_Rte_NvmBlock_PartNr_PartNrCalProgdSts: start-on-event=GetErrorStatus, operation=PS_Rte_NvmBlock_PartNr_PartNrCalProgdSts.GetErrorStatus
        OpEventGetErrorStatus_GetErrorStatus_PS_Rte_NvmBlock_PartNr_PartNrCcaMfgTrakg: start-on-event=GetErrorStatus, operation=PS_Rte_NvmBlock_PartNr_PartNrCcaMfgTrakg.GetErrorStatus
        OpEventGetErrorStatus_GetErrorStatus_PS_Rte_NvmBlock_PartNr_PartNrCtrlPidSeedKey: start-on-event=GetErrorStatus, operation=PS_Rte_NvmBlock_PartNr_PartNrCtrlPidSeedKey.GetErrorStatus
        OpEventGetErrorStatus_GetErrorStatus_PS_Rte_NvmBlock_PartNr_PartNrCustMfgEnaCntr: start-on-event=GetErrorStatus, operation=PS_Rte_NvmBlock_PartNr_PartNrCustMfgEnaCntr.GetErrorStatus
        OpEventGetErrorStatus_GetErrorStatus_PS_Rte_NvmBlock_PartNr_PartNrDataUniversalNrSysId: start-on-event=GetErrorStatus, operation=PS_Rte_NvmBlock_PartNr_PartNrDataUniversalNrSysId.GetErrorStatus
        OpEventGetErrorStatus_GetErrorStatus_PS_Rte_NvmBlock_PartNr_PartNrEndMdlPartNr: start-on-event=GetErrorStatus, operation=PS_Rte_NvmBlock_PartNr_PartNrEndMdlPartNr.GetErrorStatus
        OpEventGetErrorStatus_GetErrorStatus_PS_Rte_NvmBlock_PartNr_PartNrNxtrMfgTrakg: start-on-event=GetErrorStatus, operation=PS_Rte_NvmBlock_PartNr_PartNrNxtrMfgTrakg.GetErrorStatus
        OpEventGetErrorStatus_GetErrorStatus_PS_Rte_NvmBlock_PartNr_PartNrProgmDate: start-on-event=GetErrorStatus, operation=PS_Rte_NvmBlock_PartNr_PartNrProgmDate.GetErrorStatus
        OpEventGetErrorStatus_GetErrorStatus_PS_Rte_NvmBlock_PartNr_PartNrProgmSessionSeedKey: start-on-event=GetErrorStatus, operation=PS_Rte_NvmBlock_PartNr_PartNrProgmSessionSeedKey.GetErrorStatus
        OpEventGetErrorStatus_GetErrorStatus_PS_Rte_NvmBlock_PartNr_PartNrRepairShopCod: start-on-event=GetErrorStatus, operation=PS_Rte_NvmBlock_PartNr_PartNrRepairShopCod.GetErrorStatus
        OpEventGetErrorStatus_GetErrorStatus_PS_Rte_NvmBlock_PartNr_PartNrSysCodVersNr: start-on-event=GetErrorStatus, operation=PS_Rte_NvmBlock_PartNr_PartNrSysCodVersNr.GetErrorStatus
        OpEventGetErrorStatus_GetErrorStatus_PS_Rte_NvmBlock_PartNr_PartNrSysName: start-on-event=GetErrorStatus, operation=PS_Rte_NvmBlock_PartNr_PartNrSysName.GetErrorStatus
        OpEventGetErrorStatus_GetErrorStatus_PS_Rte_NvmBlock_PartNr_PartNrVinData: start-on-event=GetErrorStatus, operation=PS_Rte_NvmBlock_PartNr_PartNrVinData.GetErrorStatus
        OpEventGetErrorStatus_GetErrorStatus_PS_Rte_NvmBlock_PullCmpActv_PullCmpLongTerm: start-on-event=GetErrorStatus, operation=PS_Rte_NvmBlock_PullCmpActv_PullCmpLongTerm.GetErrorStatus
        OpEventGetErrorStatus_GetErrorStatus_PS_Rte_NvmBlock_SnsrOffsLrng_SnsrOffsLrnd: start-on-event=GetErrorStatus, operation=PS_Rte_NvmBlock_SnsrOffsLrng_SnsrOffsLrnd.GetErrorStatus
        OpEventInvalidateNvBlock_InvalidateNvBlock_PS_CurrMeasMotEol_Deprecated: start-on-event=InvalidateNvBlock, operation=PS_CurrMeasMotEol_Deprecated.InvalidateNvBlock
        OpEventInvalidateNvBlock_InvalidateNvBlock_PS_Rte_NvmBlock_CDD_CurrMeas_CurrMeasEolGainCalSet: start-on-event=InvalidateNvBlock, operation=PS_Rte_NvmBlock_CDD_CurrMeas_CurrMeasEolGainCalSet.InvalidateNvBlock
        OpEventInvalidateNvBlock_InvalidateNvBlock_PS_Rte_NvmBlock_CDD_CurrMeas_CurrMeasEolOffsCalSet: start-on-event=InvalidateNvBlock, operation=PS_Rte_NvmBlock_CDD_CurrMeas_CurrMeasEolOffsCalSet.InvalidateNvBlock
        OpEventInvalidateNvBlock_InvalidateNvBlock_PS_Rte_NvmBlock_CDD_HwTq{0..3}Meas_HwTq{0..3}Offs: start-on-event=InvalidateNvBlock, operation=PS_Rte_NvmBlock_CDD_HwTq{0..3}Meas_HwTq{0..3}Offs.InvalidateNvBlock
        OpEventInvalidateNvBlock_InvalidateNvBlock_PS_Rte_NvmBlock_CDD_MotAgCmp_MotAgCmpMotAgBackEmf: start-on-event=InvalidateNvBlock, operation=PS_Rte_NvmBlock_CDD_MotAgCmp_MotAgCmpMotAgBackEmf.InvalidateNvBlock
        OpEventInvalidateNvBlock_InvalidateNvBlock_PS_Rte_NvmBlock_CmnMfgSrv_IgnCntr: start-on-event=InvalidateNvBlock, operation=PS_Rte_NvmBlock_CmnMfgSrv_IgnCntr.InvalidateNvBlock
        OpEventInvalidateNvBlock_InvalidateNvBlock_PS_Rte_NvmBlock_CmnMfgSrv_NxtrMfgEnaCntr: start-on-event=InvalidateNvBlock, operation=PS_Rte_NvmBlock_CmnMfgSrv_NxtrMfgEnaCntr.InvalidateNvBlock
        OpEventInvalidateNvBlock_InvalidateNvBlock_PS_Rte_NvmBlock_DiagcMgr_DiagcMgrNtcFltAry: start-on-event=InvalidateNvBlock, operation=PS_Rte_NvmBlock_DiagcMgr_DiagcMgrNtcFltAry.InvalidateNvBlock
        OpEventInvalidateNvBlock_InvalidateNvBlock_PS_Rte_NvmBlock_DutyCycThermProtn_FilStVal: start-on-event=InvalidateNvBlock, operation=PS_Rte_NvmBlock_DutyCycThermProtn_FilStVal.InvalidateNvBlock
        OpEventInvalidateNvBlock_InvalidateNvBlock_PS_Rte_NvmBlock_EotLrng_EotNvmData: start-on-event=InvalidateNvBlock, operation=PS_Rte_NvmBlock_EotLrng_EotNvmData.InvalidateNvBlock
        OpEventInvalidateNvBlock_InvalidateNvBlock_PS_Rte_NvmBlock_GmOvrlStMgr_GmLoaIgnCntr: start-on-event=InvalidateNvBlock, operation=PS_Rte_NvmBlock_GmOvrlStMgr_GmLoaIgnCntr.InvalidateNvBlock
        OpEventInvalidateNvBlock_InvalidateNvBlock_PS_Rte_NvmBlock_HwAg0Meas_HwAg0Offs: start-on-event=InvalidateNvBlock, operation=PS_Rte_NvmBlock_HwAg0Meas_HwAg0Offs.InvalidateNvBlock
        OpEventInvalidateNvBlock_InvalidateNvBlock_PS_Rte_NvmBlock_HwAg1Meas_HwAg1Offs: start-on-event=InvalidateNvBlock, operation=PS_Rte_NvmBlock_HwAg1Meas_HwAg1Offs.InvalidateNvBlock
        OpEventInvalidateNvBlock_InvalidateNvBlock_PS_Rte_NvmBlock_HwTqCorrln_HwTqChACmnModCmpLpFilSt: start-on-event=InvalidateNvBlock, operation=PS_Rte_NvmBlock_HwTqCorrln_HwTqChACmnModCmpLpFilSt.InvalidateNvBlock
        OpEventInvalidateNvBlock_InvalidateNvBlock_PS_Rte_NvmBlock_HwTqCorrln_HwTqChBCmnModCmpLpFilSt: start-on-event=InvalidateNvBlock, operation=PS_Rte_NvmBlock_HwTqCorrln_HwTqChBCmnModCmpLpFilSt.InvalidateNvBlock
        OpEventInvalidateNvBlock_InvalidateNvBlock_PS_Rte_NvmBlock_MotAg2Meas_MotAg2EolPrm: start-on-event=InvalidateNvBlock, operation=PS_Rte_NvmBlock_MotAg2Meas_MotAg2EolPrm.InvalidateNvBlock
        OpEventInvalidateNvBlock_InvalidateNvBlock_PS_Rte_NvmBlock_NvMProxy_ShtdwnClsChk: start-on-event=InvalidateNvBlock, operation=PS_Rte_NvmBlock_NvMProxy_ShtdwnClsChk.InvalidateNvBlock
        OpEventInvalidateNvBlock_InvalidateNvBlock_PS_Rte_NvmBlock_PartNr_PartNrBasMdlPartNr: start-on-event=InvalidateNvBlock, operation=PS_Rte_NvmBlock_PartNr_PartNrBasMdlPartNr.InvalidateNvBlock
        OpEventInvalidateNvBlock_InvalidateNvBlock_PS_Rte_NvmBlock_PartNr_PartNrCalProgdSts: start-on-event=InvalidateNvBlock, operation=PS_Rte_NvmBlock_PartNr_PartNrCalProgdSts.InvalidateNvBlock
        OpEventInvalidateNvBlock_InvalidateNvBlock_PS_Rte_NvmBlock_PartNr_PartNrCcaMfgTrakg: start-on-event=InvalidateNvBlock, operation=PS_Rte_NvmBlock_PartNr_PartNrCcaMfgTrakg.InvalidateNvBlock
        OpEventInvalidateNvBlock_InvalidateNvBlock_PS_Rte_NvmBlock_PartNr_PartNrCtrlPidSeedKey: start-on-event=InvalidateNvBlock, operation=PS_Rte_NvmBlock_PartNr_PartNrCtrlPidSeedKey.InvalidateNvBlock
        OpEventInvalidateNvBlock_InvalidateNvBlock_PS_Rte_NvmBlock_PartNr_PartNrCustMfgEnaCntr: start-on-event=InvalidateNvBlock, operation=PS_Rte_NvmBlock_PartNr_PartNrCustMfgEnaCntr.InvalidateNvBlock
        OpEventInvalidateNvBlock_InvalidateNvBlock_PS_Rte_NvmBlock_PartNr_PartNrDataUniversalNrSysId: start-on-event=InvalidateNvBlock, operation=PS_Rte_NvmBlock_PartNr_PartNrDataUniversalNrSysId.InvalidateNvBlock
        OpEventInvalidateNvBlock_InvalidateNvBlock_PS_Rte_NvmBlock_PartNr_PartNrEndMdlPartNr: start-on-event=InvalidateNvBlock, operation=PS_Rte_NvmBlock_PartNr_PartNrEndMdlPartNr.InvalidateNvBlock
        OpEventInvalidateNvBlock_InvalidateNvBlock_PS_Rte_NvmBlock_PartNr_PartNrNxtrMfgTrakg: start-on-event=InvalidateNvBlock, operation=PS_Rte_NvmBlock_PartNr_PartNrNxtrMfgTrakg.InvalidateNvBlock
        OpEventInvalidateNvBlock_InvalidateNvBlock_PS_Rte_NvmBlock_PartNr_PartNrProgmDate: start-on-event=InvalidateNvBlock, operation=PS_Rte_NvmBlock_PartNr_PartNrProgmDate.InvalidateNvBlock
        OpEventInvalidateNvBlock_InvalidateNvBlock_PS_Rte_NvmBlock_PartNr_PartNrProgmSessionSeedKey: start-on-event=InvalidateNvBlock, operation=PS_Rte_NvmBlock_PartNr_PartNrProgmSessionSeedKey.InvalidateNvBlock
        OpEventInvalidateNvBlock_InvalidateNvBlock_PS_Rte_NvmBlock_PartNr_PartNrRepairShopCod: start-on-event=InvalidateNvBlock, operation=PS_Rte_NvmBlock_PartNr_PartNrRepairShopCod.InvalidateNvBlock
        OpEventInvalidateNvBlock_InvalidateNvBlock_PS_Rte_NvmBlock_PartNr_PartNrSysCodVersNr: start-on-event=InvalidateNvBlock, operation=PS_Rte_NvmBlock_PartNr_PartNrSysCodVersNr.InvalidateNvBlock
        OpEventInvalidateNvBlock_InvalidateNvBlock_PS_Rte_NvmBlock_PartNr_PartNrSysName: start-on-event=InvalidateNvBlock, operation=PS_Rte_NvmBlock_PartNr_PartNrSysName.InvalidateNvBlock
        OpEventInvalidateNvBlock_InvalidateNvBlock_PS_Rte_NvmBlock_PartNr_PartNrVinData: start-on-event=InvalidateNvBlock, operation=PS_Rte_NvmBlock_PartNr_PartNrVinData.InvalidateNvBlock
        OpEventInvalidateNvBlock_InvalidateNvBlock_PS_Rte_NvmBlock_PullCmpActv_PullCmpLongTerm: start-on-event=InvalidateNvBlock, operation=PS_Rte_NvmBlock_PullCmpActv_PullCmpLongTerm.InvalidateNvBlock
        OpEventInvalidateNvBlock_InvalidateNvBlock_PS_Rte_NvmBlock_SnsrOffsLrng_SnsrOffsLrnd: start-on-event=InvalidateNvBlock, operation=PS_Rte_NvmBlock_SnsrOffsLrng_SnsrOffsLrnd.InvalidateNvBlock
      timing event Timer_NvM_MainFunction: start-on-event=NvM_MainFunction, period=0.01
      175 x operation invoked event:
        OpEventReadBlock_ReadBlock_PS_CurrMeasMotEol_Deprecated: start-on-event=ReadBlock, operation=PS_CurrMeasMotEol_Deprecated.ReadBlock
        OpEventReadBlock_ReadBlock_PS_Rte_NvmBlock_CDD_CurrMeas_CurrMeasEolGainCalSet: start-on-event=ReadBlock, operation=PS_Rte_NvmBlock_CDD_CurrMeas_CurrMeasEolGainCalSet.ReadBlock
        OpEventReadBlock_ReadBlock_PS_Rte_NvmBlock_CDD_CurrMeas_CurrMeasEolOffsCalSet: start-on-event=ReadBlock, operation=PS_Rte_NvmBlock_CDD_CurrMeas_CurrMeasEolOffsCalSet.ReadBlock
        OpEventReadBlock_ReadBlock_PS_Rte_NvmBlock_CDD_HwTq{0..3}Meas_HwTq{0..3}Offs: start-on-event=ReadBlock, operation=PS_Rte_NvmBlock_CDD_HwTq{0..3}Meas_HwTq{0..3}Offs.ReadBlock
        OpEventReadBlock_ReadBlock_PS_Rte_NvmBlock_CDD_MotAgCmp_MotAgCmpMotAgBackEmf: start-on-event=ReadBlock, operation=PS_Rte_NvmBlock_CDD_MotAgCmp_MotAgCmpMotAgBackEmf.ReadBlock
        OpEventReadBlock_ReadBlock_PS_Rte_NvmBlock_CmnMfgSrv_IgnCntr: start-on-event=ReadBlock, operation=PS_Rte_NvmBlock_CmnMfgSrv_IgnCntr.ReadBlock
        OpEventReadBlock_ReadBlock_PS_Rte_NvmBlock_CmnMfgSrv_NxtrMfgEnaCntr: start-on-event=ReadBlock, operation=PS_Rte_NvmBlock_CmnMfgSrv_NxtrMfgEnaCntr.ReadBlock
        OpEventReadBlock_ReadBlock_PS_Rte_NvmBlock_DiagcMgr_DiagcMgrNtcFltAry: start-on-event=ReadBlock, operation=PS_Rte_NvmBlock_DiagcMgr_DiagcMgrNtcFltAry.ReadBlock
        OpEventReadBlock_ReadBlock_PS_Rte_NvmBlock_DutyCycThermProtn_FilStVal: start-on-event=ReadBlock, operation=PS_Rte_NvmBlock_DutyCycThermProtn_FilStVal.ReadBlock
        OpEventReadBlock_ReadBlock_PS_Rte_NvmBlock_EotLrng_EotNvmData: start-on-event=ReadBlock, operation=PS_Rte_NvmBlock_EotLrng_EotNvmData.ReadBlock
        OpEventReadBlock_ReadBlock_PS_Rte_NvmBlock_GmOvrlStMgr_GmLoaIgnCntr: start-on-event=ReadBlock, operation=PS_Rte_NvmBlock_GmOvrlStMgr_GmLoaIgnCntr.ReadBlock
        OpEventReadBlock_ReadBlock_PS_Rte_NvmBlock_HwAg0Meas_HwAg0Offs: start-on-event=ReadBlock, operation=PS_Rte_NvmBlock_HwAg0Meas_HwAg0Offs.ReadBlock
        OpEventReadBlock_ReadBlock_PS_Rte_NvmBlock_HwAg1Meas_HwAg1Offs: start-on-event=ReadBlock, operation=PS_Rte_NvmBlock_HwAg1Meas_HwAg1Offs.ReadBlock
        OpEventReadBlock_ReadBlock_PS_Rte_NvmBlock_HwTqCorrln_HwTqChACmnModCmpLpFilSt: start-on-event=ReadBlock, operation=PS_Rte_NvmBlock_HwTqCorrln_HwTqChACmnModCmpLpFilSt.ReadBlock
        OpEventReadBlock_ReadBlock_PS_Rte_NvmBlock_HwTqCorrln_HwTqChBCmnModCmpLpFilSt: start-on-event=ReadBlock, operation=PS_Rte_NvmBlock_HwTqCorrln_HwTqChBCmnModCmpLpFilSt.ReadBlock
        OpEventReadBlock_ReadBlock_PS_Rte_NvmBlock_MotAg2Meas_MotAg2EolPrm: start-on-event=ReadBlock, operation=PS_Rte_NvmBlock_MotAg2Meas_MotAg2EolPrm.ReadBlock
        OpEventReadBlock_ReadBlock_PS_Rte_NvmBlock_NvMProxy_ShtdwnClsChk: start-on-event=ReadBlock, operation=PS_Rte_NvmBlock_NvMProxy_ShtdwnClsChk.ReadBlock
        OpEventReadBlock_ReadBlock_PS_Rte_NvmBlock_PartNr_PartNrBasMdlPartNr: start-on-event=ReadBlock, operation=PS_Rte_NvmBlock_PartNr_PartNrBasMdlPartNr.ReadBlock
        OpEventReadBlock_ReadBlock_PS_Rte_NvmBlock_PartNr_PartNrCalProgdSts: start-on-event=ReadBlock, operation=PS_Rte_NvmBlock_PartNr_PartNrCalProgdSts.ReadBlock
        OpEventReadBlock_ReadBlock_PS_Rte_NvmBlock_PartNr_PartNrCcaMfgTrakg: start-on-event=ReadBlock, operation=PS_Rte_NvmBlock_PartNr_PartNrCcaMfgTrakg.ReadBlock
        OpEventReadBlock_ReadBlock_PS_Rte_NvmBlock_PartNr_PartNrCtrlPidSeedKey: start-on-event=ReadBlock, operation=PS_Rte_NvmBlock_PartNr_PartNrCtrlPidSeedKey.ReadBlock
        OpEventReadBlock_ReadBlock_PS_Rte_NvmBlock_PartNr_PartNrCustMfgEnaCntr: start-on-event=ReadBlock, operation=PS_Rte_NvmBlock_PartNr_PartNrCustMfgEnaCntr.ReadBlock
        OpEventReadBlock_ReadBlock_PS_Rte_NvmBlock_PartNr_PartNrDataUniversalNrSysId: start-on-event=ReadBlock, operation=PS_Rte_NvmBlock_PartNr_PartNrDataUniversalNrSysId.ReadBlock
        OpEventReadBlock_ReadBlock_PS_Rte_NvmBlock_PartNr_PartNrEndMdlPartNr: start-on-event=ReadBlock, operation=PS_Rte_NvmBlock_PartNr_PartNrEndMdlPartNr.ReadBlock
        OpEventReadBlock_ReadBlock_PS_Rte_NvmBlock_PartNr_PartNrNxtrMfgTrakg: start-on-event=ReadBlock, operation=PS_Rte_NvmBlock_PartNr_PartNrNxtrMfgTrakg.ReadBlock
        OpEventReadBlock_ReadBlock_PS_Rte_NvmBlock_PartNr_PartNrProgmDate: start-on-event=ReadBlock, operation=PS_Rte_NvmBlock_PartNr_PartNrProgmDate.ReadBlock
        OpEventReadBlock_ReadBlock_PS_Rte_NvmBlock_PartNr_PartNrProgmSessionSeedKey: start-on-event=ReadBlock, operation=PS_Rte_NvmBlock_PartNr_PartNrProgmSessionSeedKey.ReadBlock
        OpEventReadBlock_ReadBlock_PS_Rte_NvmBlock_PartNr_PartNrRepairShopCod: start-on-event=ReadBlock, operation=PS_Rte_NvmBlock_PartNr_PartNrRepairShopCod.ReadBlock
        OpEventReadBlock_ReadBlock_PS_Rte_NvmBlock_PartNr_PartNrSysCodVersNr: start-on-event=ReadBlock, operation=PS_Rte_NvmBlock_PartNr_PartNrSysCodVersNr.ReadBlock
        OpEventReadBlock_ReadBlock_PS_Rte_NvmBlock_PartNr_PartNrSysName: start-on-event=ReadBlock, operation=PS_Rte_NvmBlock_PartNr_PartNrSysName.ReadBlock
        OpEventReadBlock_ReadBlock_PS_Rte_NvmBlock_PartNr_PartNrVinData: start-on-event=ReadBlock, operation=PS_Rte_NvmBlock_PartNr_PartNrVinData.ReadBlock
        OpEventReadBlock_ReadBlock_PS_Rte_NvmBlock_PullCmpActv_PullCmpLongTerm: start-on-event=ReadBlock, operation=PS_Rte_NvmBlock_PullCmpActv_PullCmpLongTerm.ReadBlock
        OpEventReadBlock_ReadBlock_PS_Rte_NvmBlock_SnsrOffsLrng_SnsrOffsLrnd: start-on-event=ReadBlock, operation=PS_Rte_NvmBlock_SnsrOffsLrng_SnsrOffsLrnd.ReadBlock
        OpEventRestoreBlockDefaults_RestoreBlockDefaults_PS_Rte_NvmBlock_CDD_CurrMeas_CurrMeasEolGainCalSet: start-on-event=RestoreBlockDefaults, operation=PS_Rte_NvmBlock_CDD_CurrMeas_CurrMeasEolGainCalSet.RestoreBlockDefaults
        OpEventRestoreBlockDefaults_RestoreBlockDefaults_PS_Rte_NvmBlock_CDD_CurrMeas_CurrMeasEolOffsCalSet: start-on-event=RestoreBlockDefaults, operation=PS_Rte_NvmBlock_CDD_CurrMeas_CurrMeasEolOffsCalSet.RestoreBlockDefaults
        OpEventRestoreBlockDefaults_RestoreBlockDefaults_PS_Rte_NvmBlock_CDD_HwTq{0..3}Meas_HwTq{0..3}Offs: start-on-event=RestoreBlockDefaults, operation=PS_Rte_NvmBlock_CDD_HwTq{0..3}Meas_HwTq{0..3}Offs.RestoreBlockDefaults
        OpEventRestoreBlockDefaults_RestoreBlockDefaults_PS_Rte_NvmBlock_CDD_MotAgCmp_MotAgCmpMotAgBackEmf: start-on-event=RestoreBlockDefaults, operation=PS_Rte_NvmBlock_CDD_MotAgCmp_MotAgCmpMotAgBackEmf.RestoreBlockDefaults
        OpEventRestoreBlockDefaults_RestoreBlockDefaults_PS_Rte_NvmBlock_CmnMfgSrv_IgnCntr: start-on-event=RestoreBlockDefaults, operation=PS_Rte_NvmBlock_CmnMfgSrv_IgnCntr.RestoreBlockDefaults
        OpEventRestoreBlockDefaults_RestoreBlockDefaults_PS_Rte_NvmBlock_CmnMfgSrv_NxtrMfgEnaCntr: start-on-event=RestoreBlockDefaults, operation=PS_Rte_NvmBlock_CmnMfgSrv_NxtrMfgEnaCntr.RestoreBlockDefaults
        OpEventRestoreBlockDefaults_RestoreBlockDefaults_PS_Rte_NvmBlock_DutyCycThermProtn_FilStVal: start-on-event=RestoreBlockDefaults, operation=PS_Rte_NvmBlock_DutyCycThermProtn_FilStVal.RestoreBlockDefaults
        OpEventRestoreBlockDefaults_RestoreBlockDefaults_PS_Rte_NvmBlock_EotLrng_EotNvmData: start-on-event=RestoreBlockDefaults, operation=PS_Rte_NvmBlock_EotLrng_EotNvmData.RestoreBlockDefaults
        OpEventRestoreBlockDefaults_RestoreBlockDefaults_PS_Rte_NvmBlock_HwAg0Meas_HwAg0Offs: start-on-event=RestoreBlockDefaults, operation=PS_Rte_NvmBlock_HwAg0Meas_HwAg0Offs.RestoreBlockDefaults
        OpEventRestoreBlockDefaults_RestoreBlockDefaults_PS_Rte_NvmBlock_HwAg1Meas_HwAg1Offs: start-on-event=RestoreBlockDefaults, operation=PS_Rte_NvmBlock_HwAg1Meas_HwAg1Offs.RestoreBlockDefaults
        OpEventRestoreBlockDefaults_RestoreBlockDefaults_PS_Rte_NvmBlock_HwTqCorrln_HwTqChACmnModCmpLpFilSt: start-on-event=RestoreBlockDefaults, operation=PS_Rte_NvmBlock_HwTqCorrln_HwTqChACmnModCmpLpFilSt.RestoreBlockDefaults
        OpEventRestoreBlockDefaults_RestoreBlockDefaults_PS_Rte_NvmBlock_HwTqCorrln_HwTqChBCmnModCmpLpFilSt: start-on-event=RestoreBlockDefaults, operation=PS_Rte_NvmBlock_HwTqCorrln_HwTqChBCmnModCmpLpFilSt.RestoreBlockDefaults
        OpEventRestoreBlockDefaults_RestoreBlockDefaults_PS_Rte_NvmBlock_MotAg2Meas_MotAg2EolPrm: start-on-event=RestoreBlockDefaults, operation=PS_Rte_NvmBlock_MotAg2Meas_MotAg2EolPrm.RestoreBlockDefaults
        OpEventRestoreBlockDefaults_RestoreBlockDefaults_PS_Rte_NvmBlock_PartNr_PartNrBasMdlPartNr: start-on-event=RestoreBlockDefaults, operation=PS_Rte_NvmBlock_PartNr_PartNrBasMdlPartNr.RestoreBlockDefaults
        OpEventRestoreBlockDefaults_RestoreBlockDefaults_PS_Rte_NvmBlock_PartNr_PartNrCalProgdSts: start-on-event=RestoreBlockDefaults, operation=PS_Rte_NvmBlock_PartNr_PartNrCalProgdSts.RestoreBlockDefaults
        OpEventRestoreBlockDefaults_RestoreBlockDefaults_PS_Rte_NvmBlock_PartNr_PartNrCcaMfgTrakg: start-on-event=RestoreBlockDefaults, operation=PS_Rte_NvmBlock_PartNr_PartNrCcaMfgTrakg.RestoreBlockDefaults
        OpEventRestoreBlockDefaults_RestoreBlockDefaults_PS_Rte_NvmBlock_PartNr_PartNrCtrlPidSeedKey: start-on-event=RestoreBlockDefaults, operation=PS_Rte_NvmBlock_PartNr_PartNrCtrlPidSeedKey.RestoreBlockDefaults
        OpEventRestoreBlockDefaults_RestoreBlockDefaults_PS_Rte_NvmBlock_PartNr_PartNrCustMfgEnaCntr: start-on-event=RestoreBlockDefaults, operation=PS_Rte_NvmBlock_PartNr_PartNrCustMfgEnaCntr.RestoreBlockDefaults
        OpEventRestoreBlockDefaults_RestoreBlockDefaults_PS_Rte_NvmBlock_PartNr_PartNrDataUniversalNrSysId: start-on-event=RestoreBlockDefaults, operation=PS_Rte_NvmBlock_PartNr_PartNrDataUniversalNrSysId.RestoreBlockDefaults
        OpEventRestoreBlockDefaults_RestoreBlockDefaults_PS_Rte_NvmBlock_PartNr_PartNrEndMdlPartNr: start-on-event=RestoreBlockDefaults, operation=PS_Rte_NvmBlock_PartNr_PartNrEndMdlPartNr.RestoreBlockDefaults
        OpEventRestoreBlockDefaults_RestoreBlockDefaults_PS_Rte_NvmBlock_PartNr_PartNrNxtrMfgTrakg: start-on-event=RestoreBlockDefaults, operation=PS_Rte_NvmBlock_PartNr_PartNrNxtrMfgTrakg.RestoreBlockDefaults
        OpEventRestoreBlockDefaults_RestoreBlockDefaults_PS_Rte_NvmBlock_PartNr_PartNrProgmDate: start-on-event=RestoreBlockDefaults, operation=PS_Rte_NvmBlock_PartNr_PartNrProgmDate.RestoreBlockDefaults
        OpEventRestoreBlockDefaults_RestoreBlockDefaults_PS_Rte_NvmBlock_PartNr_PartNrProgmSessionSeedKey: start-on-event=RestoreBlockDefaults, operation=PS_Rte_NvmBlock_PartNr_PartNrProgmSessionSeedKey.RestoreBlockDefaults
        OpEventRestoreBlockDefaults_RestoreBlockDefaults_PS_Rte_NvmBlock_PartNr_PartNrRepairShopCod: start-on-event=RestoreBlockDefaults, operation=PS_Rte_NvmBlock_PartNr_PartNrRepairShopCod.RestoreBlockDefaults
        OpEventRestoreBlockDefaults_RestoreBlockDefaults_PS_Rte_NvmBlock_PartNr_PartNrSysCodVersNr: start-on-event=RestoreBlockDefaults, operation=PS_Rte_NvmBlock_PartNr_PartNrSysCodVersNr.RestoreBlockDefaults
        OpEventRestoreBlockDefaults_RestoreBlockDefaults_PS_Rte_NvmBlock_PartNr_PartNrSysName: start-on-event=RestoreBlockDefaults, operation=PS_Rte_NvmBlock_PartNr_PartNrSysName.RestoreBlockDefaults
        OpEventRestoreBlockDefaults_RestoreBlockDefaults_PS_Rte_NvmBlock_PartNr_PartNrVinData: start-on-event=RestoreBlockDefaults, operation=PS_Rte_NvmBlock_PartNr_PartNrVinData.RestoreBlockDefaults
        OpEventRestoreBlockDefaults_RestoreBlockDefaults_PS_Rte_NvmBlock_PullCmpActv_PullCmpLongTerm: start-on-event=RestoreBlockDefaults, operation=PS_Rte_NvmBlock_PullCmpActv_PullCmpLongTerm.RestoreBlockDefaults
        OpEventSetBlockProtection_SetBlockProtection_PAdmin_CurrMeasMotEol_Deprecated: start-on-event=SetBlockProtection, operation=PAdmin_CurrMeasMotEol_Deprecated.SetBlockProtection
        OpEventSetBlockProtection_SetBlockProtection_PAdmin_Rte_NvmBlock_CDD_CurrMeas_CurrMeasEolGainCalSet: start-on-event=SetBlockProtection, operation=PAdmin_Rte_NvmBlock_CDD_CurrMeas_CurrMeasEolGainCalSet.SetBlockProtection
        OpEventSetBlockProtection_SetBlockProtection_PAdmin_Rte_NvmBlock_CDD_CurrMeas_CurrMeasEolOffsCalSet: start-on-event=SetBlockProtection, operation=PAdmin_Rte_NvmBlock_CDD_CurrMeas_CurrMeasEolOffsCalSet.SetBlockProtection
        OpEventSetBlockProtection_SetBlockProtection_PAdmin_Rte_NvmBlock_CDD_HwTq{0..3}Meas_HwTq{0..3}Offs: start-on-event=SetBlockProtection, operation=PAdmin_Rte_NvmBlock_CDD_HwTq{0..3}Meas_HwTq{0..3}Offs.SetBlockProtection
        OpEventSetBlockProtection_SetBlockProtection_PAdmin_Rte_NvmBlock_CDD_MotAgCmp_MotAgCmpMotAgBackEmf: start-on-event=SetBlockProtection, operation=PAdmin_Rte_NvmBlock_CDD_MotAgCmp_MotAgCmpMotAgBackEmf.SetBlockProtection
        OpEventSetBlockProtection_SetBlockProtection_PAdmin_Rte_NvmBlock_CmnMfgSrv_IgnCntr: start-on-event=SetBlockProtection, operation=PAdmin_Rte_NvmBlock_CmnMfgSrv_IgnCntr.SetBlockProtection
        OpEventSetBlockProtection_SetBlockProtection_PAdmin_Rte_NvmBlock_CmnMfgSrv_NxtrMfgEnaCntr: start-on-event=SetBlockProtection, operation=PAdmin_Rte_NvmBlock_CmnMfgSrv_NxtrMfgEnaCntr.SetBlockProtection
        OpEventSetBlockProtection_SetBlockProtection_PAdmin_Rte_NvmBlock_DiagcMgr_DiagcMgrNtcFltAry: start-on-event=SetBlockProtection, operation=PAdmin_Rte_NvmBlock_DiagcMgr_DiagcMgrNtcFltAry.SetBlockProtection
        OpEventSetBlockProtection_SetBlockProtection_PAdmin_Rte_NvmBlock_DutyCycThermProtn_FilStVal: start-on-event=SetBlockProtection, operation=PAdmin_Rte_NvmBlock_DutyCycThermProtn_FilStVal.SetBlockProtection
        OpEventSetBlockProtection_SetBlockProtection_PAdmin_Rte_NvmBlock_EotLrng_EotNvmData: start-on-event=SetBlockProtection, operation=PAdmin_Rte_NvmBlock_EotLrng_EotNvmData.SetBlockProtection
        OpEventSetBlockProtection_SetBlockProtection_PAdmin_Rte_NvmBlock_GmOvrlStMgr_GmLoaIgnCntr: start-on-event=SetBlockProtection, operation=PAdmin_Rte_NvmBlock_GmOvrlStMgr_GmLoaIgnCntr.SetBlockProtection
        OpEventSetBlockProtection_SetBlockProtection_PAdmin_Rte_NvmBlock_HwAg0Meas_HwAg0Offs: start-on-event=SetBlockProtection, operation=PAdmin_Rte_NvmBlock_HwAg0Meas_HwAg0Offs.SetBlockProtection
        OpEventSetBlockProtection_SetBlockProtection_PAdmin_Rte_NvmBlock_HwAg1Meas_HwAg1Offs: start-on-event=SetBlockProtection, operation=PAdmin_Rte_NvmBlock_HwAg1Meas_HwAg1Offs.SetBlockProtection
        OpEventSetBlockProtection_SetBlockProtection_PAdmin_Rte_NvmBlock_HwTqCorrln_HwTqChACmnModCmpLpFilSt: start-on-event=SetBlockProtection, operation=PAdmin_Rte_NvmBlock_HwTqCorrln_HwTqChACmnModCmpLpFilSt.SetBlockProtection
        OpEventSetBlockProtection_SetBlockProtection_PAdmin_Rte_NvmBlock_HwTqCorrln_HwTqChBCmnModCmpLpFilSt: start-on-event=SetBlockProtection, operation=PAdmin_Rte_NvmBlock_HwTqCorrln_HwTqChBCmnModCmpLpFilSt.SetBlockProtection
        OpEventSetBlockProtection_SetBlockProtection_PAdmin_Rte_NvmBlock_MotAg2Meas_MotAg2EolPrm: start-on-event=SetBlockProtection, operation=PAdmin_Rte_NvmBlock_MotAg2Meas_MotAg2EolPrm.SetBlockProtection
        OpEventSetBlockProtection_SetBlockProtection_PAdmin_Rte_NvmBlock_NvMProxy_ShtdwnClsChk: start-on-event=SetBlockProtection, operation=PAdmin_Rte_NvmBlock_NvMProxy_ShtdwnClsChk.SetBlockProtection
        OpEventSetBlockProtection_SetBlockProtection_PAdmin_Rte_NvmBlock_PartNr_PartNrBasMdlPartNr: start-on-event=SetBlockProtection, operation=PAdmin_Rte_NvmBlock_PartNr_PartNrBasMdlPartNr.SetBlockProtection
        OpEventSetBlockProtection_SetBlockProtection_PAdmin_Rte_NvmBlock_PartNr_PartNrCalProgdSts: start-on-event=SetBlockProtection, operation=PAdmin_Rte_NvmBlock_PartNr_PartNrCalProgdSts.SetBlockProtection
        OpEventSetBlockProtection_SetBlockProtection_PAdmin_Rte_NvmBlock_PartNr_PartNrCcaMfgTrakg: start-on-event=SetBlockProtection, operation=PAdmin_Rte_NvmBlock_PartNr_PartNrCcaMfgTrakg.SetBlockProtection
        OpEventSetBlockProtection_SetBlockProtection_PAdmin_Rte_NvmBlock_PartNr_PartNrCtrlPidSeedKey: start-on-event=SetBlockProtection, operation=PAdmin_Rte_NvmBlock_PartNr_PartNrCtrlPidSeedKey.SetBlockProtection
        OpEventSetBlockProtection_SetBlockProtection_PAdmin_Rte_NvmBlock_PartNr_PartNrCustMfgEnaCntr: start-on-event=SetBlockProtection, operation=PAdmin_Rte_NvmBlock_PartNr_PartNrCustMfgEnaCntr.SetBlockProtection
        OpEventSetBlockProtection_SetBlockProtection_PAdmin_Rte_NvmBlock_PartNr_PartNrDataUniversalNrSysId: start-on-event=SetBlockProtection, operation=PAdmin_Rte_NvmBlock_PartNr_PartNrDataUniversalNrSysId.SetBlockProtection
        OpEventSetBlockProtection_SetBlockProtection_PAdmin_Rte_NvmBlock_PartNr_PartNrEndMdlPartNr: start-on-event=SetBlockProtection, operation=PAdmin_Rte_NvmBlock_PartNr_PartNrEndMdlPartNr.SetBlockProtection
        OpEventSetBlockProtection_SetBlockProtection_PAdmin_Rte_NvmBlock_PartNr_PartNrNxtrMfgTrakg: start-on-event=SetBlockProtection, operation=PAdmin_Rte_NvmBlock_PartNr_PartNrNxtrMfgTrakg.SetBlockProtection
        OpEventSetBlockProtection_SetBlockProtection_PAdmin_Rte_NvmBlock_PartNr_PartNrProgmDate: start-on-event=SetBlockProtection, operation=PAdmin_Rte_NvmBlock_PartNr_PartNrProgmDate.SetBlockProtection
        OpEventSetBlockProtection_SetBlockProtection_PAdmin_Rte_NvmBlock_PartNr_PartNrProgmSessionSeedKey: start-on-event=SetBlockProtection, operation=PAdmin_Rte_NvmBlock_PartNr_PartNrProgmSessionSeedKey.SetBlockProtection
        OpEventSetBlockProtection_SetBlockProtection_PAdmin_Rte_NvmBlock_PartNr_PartNrRepairShopCod: start-on-event=SetBlockProtection, operation=PAdmin_Rte_NvmBlock_PartNr_PartNrRepairShopCod.SetBlockProtection
        OpEventSetBlockProtection_SetBlockProtection_PAdmin_Rte_NvmBlock_PartNr_PartNrSysCodVersNr: start-on-event=SetBlockProtection, operation=PAdmin_Rte_NvmBlock_PartNr_PartNrSysCodVersNr.SetBlockProtection
        OpEventSetBlockProtection_SetBlockProtection_PAdmin_Rte_NvmBlock_PartNr_PartNrSysName: start-on-event=SetBlockProtection, operation=PAdmin_Rte_NvmBlock_PartNr_PartNrSysName.SetBlockProtection
        OpEventSetBlockProtection_SetBlockProtection_PAdmin_Rte_NvmBlock_PartNr_PartNrVinData: start-on-event=SetBlockProtection, operation=PAdmin_Rte_NvmBlock_PartNr_PartNrVinData.SetBlockProtection
        OpEventSetBlockProtection_SetBlockProtection_PAdmin_Rte_NvmBlock_PullCmpActv_PullCmpLongTerm: start-on-event=SetBlockProtection, operation=PAdmin_Rte_NvmBlock_PullCmpActv_PullCmpLongTerm.SetBlockProtection
        OpEventSetBlockProtection_SetBlockProtection_PAdmin_Rte_NvmBlock_SnsrOffsLrng_SnsrOffsLrnd: start-on-event=SetBlockProtection, operation=PAdmin_Rte_NvmBlock_SnsrOffsLrng_SnsrOffsLrnd.SetBlockProtection
        OpEventSetRamBlockStatus_SetRamBlockStatus_PS_CurrMeasMotEol_Deprecated: start-on-event=SetRamBlockStatus, operation=PS_CurrMeasMotEol_Deprecated.SetRamBlockStatus
        OpEventSetRamBlockStatus_SetRamBlockStatus_PS_Rte_NvmBlock_CDD_CurrMeas_CurrMeasEolGainCalSet: start-on-event=SetRamBlockStatus, operation=PS_Rte_NvmBlock_CDD_CurrMeas_CurrMeasEolGainCalSet.SetRamBlockStatus
        OpEventSetRamBlockStatus_SetRamBlockStatus_PS_Rte_NvmBlock_CDD_CurrMeas_CurrMeasEolOffsCalSet: start-on-event=SetRamBlockStatus, operation=PS_Rte_NvmBlock_CDD_CurrMeas_CurrMeasEolOffsCalSet.SetRamBlockStatus
        OpEventSetRamBlockStatus_SetRamBlockStatus_PS_Rte_NvmBlock_CDD_HwTq{0..3}Meas_HwTq{0..3}Offs: start-on-event=SetRamBlockStatus, operation=PS_Rte_NvmBlock_CDD_HwTq{0..3}Meas_HwTq{0..3}Offs.SetRamBlockStatus
        OpEventSetRamBlockStatus_SetRamBlockStatus_PS_Rte_NvmBlock_CDD_MotAgCmp_MotAgCmpMotAgBackEmf: start-on-event=SetRamBlockStatus, operation=PS_Rte_NvmBlock_CDD_MotAgCmp_MotAgCmpMotAgBackEmf.SetRamBlockStatus
        OpEventSetRamBlockStatus_SetRamBlockStatus_PS_Rte_NvmBlock_CmnMfgSrv_IgnCntr: start-on-event=SetRamBlockStatus, operation=PS_Rte_NvmBlock_CmnMfgSrv_IgnCntr.SetRamBlockStatus
        OpEventSetRamBlockStatus_SetRamBlockStatus_PS_Rte_NvmBlock_CmnMfgSrv_NxtrMfgEnaCntr: start-on-event=SetRamBlockStatus, operation=PS_Rte_NvmBlock_CmnMfgSrv_NxtrMfgEnaCntr.SetRamBlockStatus
        OpEventSetRamBlockStatus_SetRamBlockStatus_PS_Rte_NvmBlock_DiagcMgr_DiagcMgrNtcFltAry: start-on-event=SetRamBlockStatus, operation=PS_Rte_NvmBlock_DiagcMgr_DiagcMgrNtcFltAry.SetRamBlockStatus
        OpEventSetRamBlockStatus_SetRamBlockStatus_PS_Rte_NvmBlock_DutyCycThermProtn_FilStVal: start-on-event=SetRamBlockStatus, operation=PS_Rte_NvmBlock_DutyCycThermProtn_FilStVal.SetRamBlockStatus
        OpEventSetRamBlockStatus_SetRamBlockStatus_PS_Rte_NvmBlock_EotLrng_EotNvmData: start-on-event=SetRamBlockStatus, operation=PS_Rte_NvmBlock_EotLrng_EotNvmData.SetRamBlockStatus
        OpEventSetRamBlockStatus_SetRamBlockStatus_PS_Rte_NvmBlock_GmOvrlStMgr_GmLoaIgnCntr: start-on-event=SetRamBlockStatus, operation=PS_Rte_NvmBlock_GmOvrlStMgr_GmLoaIgnCntr.SetRamBlockStatus
        OpEventSetRamBlockStatus_SetRamBlockStatus_PS_Rte_NvmBlock_HwAg0Meas_HwAg0Offs: start-on-event=SetRamBlockStatus, operation=PS_Rte_NvmBlock_HwAg0Meas_HwAg0Offs.SetRamBlockStatus
        OpEventSetRamBlockStatus_SetRamBlockStatus_PS_Rte_NvmBlock_HwAg1Meas_HwAg1Offs: start-on-event=SetRamBlockStatus, operation=PS_Rte_NvmBlock_HwAg1Meas_HwAg1Offs.SetRamBlockStatus
        OpEventSetRamBlockStatus_SetRamBlockStatus_PS_Rte_NvmBlock_HwTqCorrln_HwTqChACmnModCmpLpFilSt: start-on-event=SetRamBlockStatus, operation=PS_Rte_NvmBlock_HwTqCorrln_HwTqChACmnModCmpLpFilSt.SetRamBlockStatus
        OpEventSetRamBlockStatus_SetRamBlockStatus_PS_Rte_NvmBlock_HwTqCorrln_HwTqChBCmnModCmpLpFilSt: start-on-event=SetRamBlockStatus, operation=PS_Rte_NvmBlock_HwTqCorrln_HwTqChBCmnModCmpLpFilSt.SetRamBlockStatus
        OpEventSetRamBlockStatus_SetRamBlockStatus_PS_Rte_NvmBlock_MotAg2Meas_MotAg2EolPrm: start-on-event=SetRamBlockStatus, operation=PS_Rte_NvmBlock_MotAg2Meas_MotAg2EolPrm.SetRamBlockStatus
        OpEventSetRamBlockStatus_SetRamBlockStatus_PS_Rte_NvmBlock_NvMProxy_ShtdwnClsChk: start-on-event=SetRamBlockStatus, operation=PS_Rte_NvmBlock_NvMProxy_ShtdwnClsChk.SetRamBlockStatus
        OpEventSetRamBlockStatus_SetRamBlockStatus_PS_Rte_NvmBlock_PartNr_PartNrBasMdlPartNr: start-on-event=SetRamBlockStatus, operation=PS_Rte_NvmBlock_PartNr_PartNrBasMdlPartNr.SetRamBlockStatus
        OpEventSetRamBlockStatus_SetRamBlockStatus_PS_Rte_NvmBlock_PartNr_PartNrCalProgdSts: start-on-event=SetRamBlockStatus, operation=PS_Rte_NvmBlock_PartNr_PartNrCalProgdSts.SetRamBlockStatus
        OpEventSetRamBlockStatus_SetRamBlockStatus_PS_Rte_NvmBlock_PartNr_PartNrCcaMfgTrakg: start-on-event=SetRamBlockStatus, operation=PS_Rte_NvmBlock_PartNr_PartNrCcaMfgTrakg.SetRamBlockStatus
        OpEventSetRamBlockStatus_SetRamBlockStatus_PS_Rte_NvmBlock_PartNr_PartNrCtrlPidSeedKey: start-on-event=SetRamBlockStatus, operation=PS_Rte_NvmBlock_PartNr_PartNrCtrlPidSeedKey.SetRamBlockStatus
        OpEventSetRamBlockStatus_SetRamBlockStatus_PS_Rte_NvmBlock_PartNr_PartNrCustMfgEnaCntr: start-on-event=SetRamBlockStatus, operation=PS_Rte_NvmBlock_PartNr_PartNrCustMfgEnaCntr.SetRamBlockStatus
        OpEventSetRamBlockStatus_SetRamBlockStatus_PS_Rte_NvmBlock_PartNr_PartNrDataUniversalNrSysId: start-on-event=SetRamBlockStatus, operation=PS_Rte_NvmBlock_PartNr_PartNrDataUniversalNrSysId.SetRamBlockStatus
        OpEventSetRamBlockStatus_SetRamBlockStatus_PS_Rte_NvmBlock_PartNr_PartNrEndMdlPartNr: start-on-event=SetRamBlockStatus, operation=PS_Rte_NvmBlock_PartNr_PartNrEndMdlPartNr.SetRamBlockStatus
        OpEventSetRamBlockStatus_SetRamBlockStatus_PS_Rte_NvmBlock_PartNr_PartNrNxtrMfgTrakg: start-on-event=SetRamBlockStatus, operation=PS_Rte_NvmBlock_PartNr_PartNrNxtrMfgTrakg.SetRamBlockStatus
        OpEventSetRamBlockStatus_SetRamBlockStatus_PS_Rte_NvmBlock_PartNr_PartNrProgmDate: start-on-event=SetRamBlockStatus, operation=PS_Rte_NvmBlock_PartNr_PartNrProgmDate.SetRamBlockStatus
        OpEventSetRamBlockStatus_SetRamBlockStatus_PS_Rte_NvmBlock_PartNr_PartNrProgmSessionSeedKey: start-on-event=SetRamBlockStatus, operation=PS_Rte_NvmBlock_PartNr_PartNrProgmSessionSeedKey.SetRamBlockStatus
        OpEventSetRamBlockStatus_SetRamBlockStatus_PS_Rte_NvmBlock_PartNr_PartNrRepairShopCod: start-on-event=SetRamBlockStatus, operation=PS_Rte_NvmBlock_PartNr_PartNrRepairShopCod.SetRamBlockStatus
        OpEventSetRamBlockStatus_SetRamBlockStatus_PS_Rte_NvmBlock_PartNr_PartNrSysCodVersNr: start-on-event=SetRamBlockStatus, operation=PS_Rte_NvmBlock_PartNr_PartNrSysCodVersNr.SetRamBlockStatus
        OpEventSetRamBlockStatus_SetRamBlockStatus_PS_Rte_NvmBlock_PartNr_PartNrSysName: start-on-event=SetRamBlockStatus, operation=PS_Rte_NvmBlock_PartNr_PartNrSysName.SetRamBlockStatus
        OpEventSetRamBlockStatus_SetRamBlockStatus_PS_Rte_NvmBlock_PartNr_PartNrVinData: start-on-event=SetRamBlockStatus, operation=PS_Rte_NvmBlock_PartNr_PartNrVinData.SetRamBlockStatus
        OpEventSetRamBlockStatus_SetRamBlockStatus_PS_Rte_NvmBlock_PullCmpActv_PullCmpLongTerm: start-on-event=SetRamBlockStatus, operation=PS_Rte_NvmBlock_PullCmpActv_PullCmpLongTerm.SetRamBlockStatus
        OpEventSetRamBlockStatus_SetRamBlockStatus_PS_Rte_NvmBlock_SnsrOffsLrng_SnsrOffsLrnd: start-on-event=SetRamBlockStatus, operation=PS_Rte_NvmBlock_SnsrOffsLrng_SnsrOffsLrnd.SetRamBlockStatus
        OpEventWriteBlock_WriteBlock_PS_CurrMeasMotEol_Deprecated: start-on-event=WriteBlock, operation=PS_CurrMeasMotEol_Deprecated.WriteBlock
        OpEventWriteBlock_WriteBlock_PS_Rte_NvmBlock_CDD_CurrMeas_CurrMeasEolGainCalSet: start-on-event=WriteBlock, operation=PS_Rte_NvmBlock_CDD_CurrMeas_CurrMeasEolGainCalSet.WriteBlock
        OpEventWriteBlock_WriteBlock_PS_Rte_NvmBlock_CDD_CurrMeas_CurrMeasEolOffsCalSet: start-on-event=WriteBlock, operation=PS_Rte_NvmBlock_CDD_CurrMeas_CurrMeasEolOffsCalSet.WriteBlock
        OpEventWriteBlock_WriteBlock_PS_Rte_NvmBlock_CDD_HwTq{0..3}Meas_HwTq{0..3}Offs: start-on-event=WriteBlock, operation=PS_Rte_NvmBlock_CDD_HwTq{0..3}Meas_HwTq{0..3}Offs.WriteBlock
        OpEventWriteBlock_WriteBlock_PS_Rte_NvmBlock_CDD_MotAgCmp_MotAgCmpMotAgBackEmf: start-on-event=WriteBlock, operation=PS_Rte_NvmBlock_CDD_MotAgCmp_MotAgCmpMotAgBackEmf.WriteBlock
        OpEventWriteBlock_WriteBlock_PS_Rte_NvmBlock_CmnMfgSrv_IgnCntr: start-on-event=WriteBlock, operation=PS_Rte_NvmBlock_CmnMfgSrv_IgnCntr.WriteBlock
        OpEventWriteBlock_WriteBlock_PS_Rte_NvmBlock_CmnMfgSrv_NxtrMfgEnaCntr: start-on-event=WriteBlock, operation=PS_Rte_NvmBlock_CmnMfgSrv_NxtrMfgEnaCntr.WriteBlock
        OpEventWriteBlock_WriteBlock_PS_Rte_NvmBlock_DiagcMgr_DiagcMgrNtcFltAry: start-on-event=WriteBlock, operation=PS_Rte_NvmBlock_DiagcMgr_DiagcMgrNtcFltAry.WriteBlock
        OpEventWriteBlock_WriteBlock_PS_Rte_NvmBlock_DutyCycThermProtn_FilStVal: start-on-event=WriteBlock, operation=PS_Rte_NvmBlock_DutyCycThermProtn_FilStVal.WriteBlock
        OpEventWriteBlock_WriteBlock_PS_Rte_NvmBlock_EotLrng_EotNvmData: start-on-event=WriteBlock, operation=PS_Rte_NvmBlock_EotLrng_EotNvmData.WriteBlock
        OpEventWriteBlock_WriteBlock_PS_Rte_NvmBlock_GmOvrlStMgr_GmLoaIgnCntr: start-on-event=WriteBlock, operation=PS_Rte_NvmBlock_GmOvrlStMgr_GmLoaIgnCntr.WriteBlock
        OpEventWriteBlock_WriteBlock_PS_Rte_NvmBlock_HwAg0Meas_HwAg0Offs: start-on-event=WriteBlock, operation=PS_Rte_NvmBlock_HwAg0Meas_HwAg0Offs.WriteBlock
        OpEventWriteBlock_WriteBlock_PS_Rte_NvmBlock_HwAg1Meas_HwAg1Offs: start-on-event=WriteBlock, operation=PS_Rte_NvmBlock_HwAg1Meas_HwAg1Offs.WriteBlock
        OpEventWriteBlock_WriteBlock_PS_Rte_NvmBlock_HwTqCorrln_HwTqChACmnModCmpLpFilSt: start-on-event=WriteBlock, operation=PS_Rte_NvmBlock_HwTqCorrln_HwTqChACmnModCmpLpFilSt.WriteBlock
        OpEventWriteBlock_WriteBlock_PS_Rte_NvmBlock_HwTqCorrln_HwTqChBCmnModCmpLpFilSt: start-on-event=WriteBlock, operation=PS_Rte_NvmBlock_HwTqCorrln_HwTqChBCmnModCmpLpFilSt.WriteBlock
        OpEventWriteBlock_WriteBlock_PS_Rte_NvmBlock_MotAg2Meas_MotAg2EolPrm: start-on-event=WriteBlock, operation=PS_Rte_NvmBlock_MotAg2Meas_MotAg2EolPrm.WriteBlock
        OpEventWriteBlock_WriteBlock_PS_Rte_NvmBlock_NvMProxy_ShtdwnClsChk: start-on-event=WriteBlock, operation=PS_Rte_NvmBlock_NvMProxy_ShtdwnClsChk.WriteBlock
        OpEventWriteBlock_WriteBlock_PS_Rte_NvmBlock_PartNr_PartNrBasMdlPartNr: start-on-event=WriteBlock, operation=PS_Rte_NvmBlock_PartNr_PartNrBasMdlPartNr.WriteBlock
        OpEventWriteBlock_WriteBlock_PS_Rte_NvmBlock_PartNr_PartNrCalProgdSts: start-on-event=WriteBlock, operation=PS_Rte_NvmBlock_PartNr_PartNrCalProgdSts.WriteBlock
        OpEventWriteBlock_WriteBlock_PS_Rte_NvmBlock_PartNr_PartNrCcaMfgTrakg: start-on-event=WriteBlock, operation=PS_Rte_NvmBlock_PartNr_PartNrCcaMfgTrakg.WriteBlock
        OpEventWriteBlock_WriteBlock_PS_Rte_NvmBlock_PartNr_PartNrCtrlPidSeedKey: start-on-event=WriteBlock, operation=PS_Rte_NvmBlock_PartNr_PartNrCtrlPidSeedKey.WriteBlock
        OpEventWriteBlock_WriteBlock_PS_Rte_NvmBlock_PartNr_PartNrCustMfgEnaCntr: start-on-event=WriteBlock, operation=PS_Rte_NvmBlock_PartNr_PartNrCustMfgEnaCntr.WriteBlock
        OpEventWriteBlock_WriteBlock_PS_Rte_NvmBlock_PartNr_PartNrDataUniversalNrSysId: start-on-event=WriteBlock, operation=PS_Rte_NvmBlock_PartNr_PartNrDataUniversalNrSysId.WriteBlock
        OpEventWriteBlock_WriteBlock_PS_Rte_NvmBlock_PartNr_PartNrEndMdlPartNr: start-on-event=WriteBlock, operation=PS_Rte_NvmBlock_PartNr_PartNrEndMdlPartNr.WriteBlock
        OpEventWriteBlock_WriteBlock_PS_Rte_NvmBlock_PartNr_PartNrNxtrMfgTrakg: start-on-event=WriteBlock, operation=PS_Rte_NvmBlock_PartNr_PartNrNxtrMfgTrakg.WriteBlock
        OpEventWriteBlock_WriteBlock_PS_Rte_NvmBlock_PartNr_PartNrProgmDate: start-on-event=WriteBlock, operation=PS_Rte_NvmBlock_PartNr_PartNrProgmDate.WriteBlock
        OpEventWriteBlock_WriteBlock_PS_Rte_NvmBlock_PartNr_PartNrProgmSessionSeedKey: start-on-event=WriteBlock, operation=PS_Rte_NvmBlock_PartNr_PartNrProgmSessionSeedKey.WriteBlock
        OpEventWriteBlock_WriteBlock_PS_Rte_NvmBlock_PartNr_PartNrRepairShopCod: start-on-event=WriteBlock, operation=PS_Rte_NvmBlock_PartNr_PartNrRepairShopCod.WriteBlock
        OpEventWriteBlock_WriteBlock_PS_Rte_NvmBlock_PartNr_PartNrSysCodVersNr: start-on-event=WriteBlock, operation=PS_Rte_NvmBlock_PartNr_PartNrSysCodVersNr.WriteBlock
        OpEventWriteBlock_WriteBlock_PS_Rte_NvmBlock_PartNr_PartNrSysName: start-on-event=WriteBlock, operation=PS_Rte_NvmBlock_PartNr_PartNrSysName.WriteBlock
        OpEventWriteBlock_WriteBlock_PS_Rte_NvmBlock_PartNr_PartNrVinData: start-on-event=WriteBlock, operation=PS_Rte_NvmBlock_PartNr_PartNrVinData.WriteBlock
        OpEventWriteBlock_WriteBlock_PS_Rte_NvmBlock_PullCmpActv_PullCmpLongTerm: start-on-event=WriteBlock, operation=PS_Rte_NvmBlock_PullCmpActv_PullCmpLongTerm.WriteBlock
        OpEventWriteBlock_WriteBlock_PS_Rte_NvmBlock_SnsrOffsLrng_SnsrOffsLrnd: start-on-event=WriteBlock, operation=PS_Rte_NvmBlock_SnsrOffsLrng_SnsrOffsLrnd.WriteBlock
      port-api-options:
        {enable-take-address=true, indirect-api=false, port-defined-argument-value{value=PAdmin_CurrMeasMotEol_Deprecated_0:2, value-type=NvM_BlockIdType}, port=PAdmin_CurrMeasMotEol_Deprecated}
        {enable-take-address=true, indirect-api=false, port-defined-argument-value{value=PAdmin_Rte_NvmBlock_CDD_CurrMeas_CurrMeasEolGainCalSet_0:95, value-type=NvM_BlockIdType}, port=PAdmin_Rte_NvmBlock_CDD_CurrMeas_CurrMeasEolGainCalSet}
        {enable-take-address=true, indirect-api=false, port-defined-argument-value{value=PAdmin_Rte_NvmBlock_CDD_CurrMeas_CurrMeasEolOffsCalSet_0:96, value-type=NvM_BlockIdType}, port=PAdmin_Rte_NvmBlock_CDD_CurrMeas_CurrMeasEolOffsCalSet}
        {enable-take-address=true, indirect-api=false, port-defined-argument-value{value=PAdmin_Rte_NvmBlock_CDD_HwTq0Meas_HwTq0Offs_0:100, value-type=NvM_BlockIdType}, port=PAdmin_Rte_NvmBlock_CDD_HwTq0Meas_HwTq0Offs}
        {enable-take-address=true, indirect-api=false, port-defined-argument-value{value=PAdmin_Rte_NvmBlock_CDD_HwTq1Meas_HwTq1Offs_0:101, value-type=NvM_BlockIdType}, port=PAdmin_Rte_NvmBlock_CDD_HwTq1Meas_HwTq1Offs}
        {enable-take-address=true, indirect-api=false, port-defined-argument-value{value=PAdmin_Rte_NvmBlock_CDD_HwTq2Meas_HwTq2Offs_0:103, value-type=NvM_BlockIdType}, port=PAdmin_Rte_NvmBlock_CDD_HwTq2Meas_HwTq2Offs}
        {enable-take-address=true, indirect-api=false, port-defined-argument-value{value=PAdmin_Rte_NvmBlock_CDD_HwTq3Meas_HwTq3Offs_0:102, value-type=NvM_BlockIdType}, port=PAdmin_Rte_NvmBlock_CDD_HwTq3Meas_HwTq3Offs}
        {enable-take-address=true, indirect-api=false, port-defined-argument-value{value=PAdmin_Rte_NvmBlock_CDD_MotAgCmp_MotAgCmpMotAgBackEmf_0:113, value-type=NvM_BlockIdType}, port=PAdmin_Rte_NvmBlock_CDD_MotAgCmp_MotAgCmpMotAgBackEmf}
        {enable-take-address=true, indirect-api=false, port-defined-argument-value{value=PAdmin_Rte_NvmBlock_CmnMfgSrv_IgnCntr_0:111, value-type=NvM_BlockIdType}, port=PAdmin_Rte_NvmBlock_CmnMfgSrv_IgnCntr}
        {enable-take-address=true, indirect-api=false, port-defined-argument-value{value=PAdmin_Rte_NvmBlock_CmnMfgSrv_NxtrMfgEnaCntr_0:110, value-type=NvM_BlockIdType}, port=PAdmin_Rte_NvmBlock_CmnMfgSrv_NxtrMfgEnaCntr}
        {enable-take-address=true, indirect-api=false, port-defined-argument-value{value=PAdmin_Rte_NvmBlock_DiagcMgr_DiagcMgrNtcFltAry_0:98, value-type=NvM_BlockIdType}, port=PAdmin_Rte_NvmBlock_DiagcMgr_DiagcMgrNtcFltAry}
        {enable-take-address=true, indirect-api=false, port-defined-argument-value{value=PAdmin_Rte_NvmBlock_DutyCycThermProtn_FilStVal_0:71, value-type=NvM_BlockIdType}, port=PAdmin_Rte_NvmBlock_DutyCycThermProtn_FilStVal}
        {enable-take-address=true, indirect-api=false, port-defined-argument-value{value=PAdmin_Rte_NvmBlock_EotLrng_EotNvmData_0:97, value-type=NvM_BlockIdType}, port=PAdmin_Rte_NvmBlock_EotLrng_EotNvmData}
        {enable-take-address=true, indirect-api=false, port-defined-argument-value{value=PAdmin_Rte_NvmBlock_GmOvrlStMgr_GmLoaIgnCntr_0:67, value-type=NvM_BlockIdType}, port=PAdmin_Rte_NvmBlock_GmOvrlStMgr_GmLoaIgnCntr}
        {enable-take-address=true, indirect-api=false, port-defined-argument-value{value=PAdmin_Rte_NvmBlock_HwAg0Meas_HwAg0Offs_0:108, value-type=NvM_BlockIdType}, port=PAdmin_Rte_NvmBlock_HwAg0Meas_HwAg0Offs}
        {enable-take-address=true, indirect-api=false, port-defined-argument-value{value=PAdmin_Rte_NvmBlock_HwAg1Meas_HwAg1Offs_0:106, value-type=NvM_BlockIdType}, port=PAdmin_Rte_NvmBlock_HwAg1Meas_HwAg1Offs}
        {enable-take-address=true, indirect-api=false, port-defined-argument-value{value=PAdmin_Rte_NvmBlock_HwTqCorrln_HwTqChACmnModCmpLpFilSt_0:104, value-type=NvM_BlockIdType}, port=PAdmin_Rte_NvmBlock_HwTqCorrln_HwTqChACmnModCmpLpFilSt}
        {enable-take-address=true, indirect-api=false, port-defined-argument-value{value=PAdmin_Rte_NvmBlock_HwTqCorrln_HwTqChBCmnModCmpLpFilSt_0:105, value-type=NvM_BlockIdType}, port=PAdmin_Rte_NvmBlock_HwTqCorrln_HwTqChBCmnModCmpLpFilSt}
        {enable-take-address=true, indirect-api=false, port-defined-argument-value{value=PAdmin_Rte_NvmBlock_MotAg2Meas_MotAg2EolPrm_0:99, value-type=NvM_BlockIdType}, port=PAdmin_Rte_NvmBlock_MotAg2Meas_MotAg2EolPrm}
        {enable-take-address=true, indirect-api=false, port-defined-argument-value{value=PAdmin_Rte_NvmBlock_NvMProxy_ShtdwnClsChk_0:107, value-type=NvM_BlockIdType}, port=PAdmin_Rte_NvmBlock_NvMProxy_ShtdwnClsChk}
        {enable-take-address=true, indirect-api=false, port-defined-argument-value{value=PAdmin_Rte_NvmBlock_PartNr_PartNrBasMdlPartNr_0:87, value-type=NvM_BlockIdType}, port=PAdmin_Rte_NvmBlock_PartNr_PartNrBasMdlPartNr}
        {enable-take-address=true, indirect-api=false, port-defined-argument-value{value=PAdmin_Rte_NvmBlock_PartNr_PartNrCalProgdSts_0:92, value-type=NvM_BlockIdType}, port=PAdmin_Rte_NvmBlock_PartNr_PartNrCalProgdSts}
        {enable-take-address=true, indirect-api=false, port-defined-argument-value{value=PAdmin_Rte_NvmBlock_PartNr_PartNrCcaMfgTrakg_0:83, value-type=NvM_BlockIdType}, port=PAdmin_Rte_NvmBlock_PartNr_PartNrCcaMfgTrakg}
        {enable-take-address=true, indirect-api=false, port-defined-argument-value{value=PAdmin_Rte_NvmBlock_PartNr_PartNrCtrlPidSeedKey_0:88, value-type=NvM_BlockIdType}, port=PAdmin_Rte_NvmBlock_PartNr_PartNrCtrlPidSeedKey}
        {enable-take-address=true, indirect-api=false, port-defined-argument-value{value=PAdmin_Rte_NvmBlock_PartNr_PartNrCustMfgEnaCntr_0:93, value-type=NvM_BlockIdType}, port=PAdmin_Rte_NvmBlock_PartNr_PartNrCustMfgEnaCntr}
        {enable-take-address=true, indirect-api=false, port-defined-argument-value{value=PAdmin_Rte_NvmBlock_PartNr_PartNrDataUniversalNrSysId_0:91, value-type=NvM_BlockIdType}, port=PAdmin_Rte_NvmBlock_PartNr_PartNrDataUniversalNrSysId}
        {enable-take-address=true, indirect-api=false, port-defined-argument-value{value=PAdmin_Rte_NvmBlock_PartNr_PartNrEndMdlPartNr_0:86, value-type=NvM_BlockIdType}, port=PAdmin_Rte_NvmBlock_PartNr_PartNrEndMdlPartNr}
        {enable-take-address=true, indirect-api=false, port-defined-argument-value{value=PAdmin_Rte_NvmBlock_PartNr_PartNrNxtrMfgTrakg_0:85, value-type=NvM_BlockIdType}, port=PAdmin_Rte_NvmBlock_PartNr_PartNrNxtrMfgTrakg}
        {enable-take-address=true, indirect-api=false, port-defined-argument-value{value=PAdmin_Rte_NvmBlock_PartNr_PartNrProgmDate_0:90, value-type=NvM_BlockIdType}, port=PAdmin_Rte_NvmBlock_PartNr_PartNrProgmDate}
        {enable-take-address=true, indirect-api=false, port-defined-argument-value{value=PAdmin_Rte_NvmBlock_PartNr_PartNrProgmSessionSeedKey_0:94, value-type=NvM_BlockIdType}, port=PAdmin_Rte_NvmBlock_PartNr_PartNrProgmSessionSeedKey}
        {enable-take-address=true, indirect-api=false, port-defined-argument-value{value=PAdmin_Rte_NvmBlock_PartNr_PartNrRepairShopCod_0:81, value-type=NvM_BlockIdType}, port=PAdmin_Rte_NvmBlock_PartNr_PartNrRepairShopCod}
        {enable-take-address=true, indirect-api=false, port-defined-argument-value{value=PAdmin_Rte_NvmBlock_PartNr_PartNrSysCodVersNr_0:84, value-type=NvM_BlockIdType}, port=PAdmin_Rte_NvmBlock_PartNr_PartNrSysCodVersNr}
        {enable-take-address=true, indirect-api=false, port-defined-argument-value{value=PAdmin_Rte_NvmBlock_PartNr_PartNrSysName_0:82, value-type=NvM_BlockIdType}, port=PAdmin_Rte_NvmBlock_PartNr_PartNrSysName}
        {enable-take-address=true, indirect-api=false, port-defined-argument-value{value=PAdmin_Rte_NvmBlock_PartNr_PartNrVinData_0:89, value-type=NvM_BlockIdType}, port=PAdmin_Rte_NvmBlock_PartNr_PartNrVinData}
        {enable-take-address=true, indirect-api=false, port-defined-argument-value{value=PAdmin_Rte_NvmBlock_PullCmpActv_PullCmpLongTerm_0:70, value-type=NvM_BlockIdType}, port=PAdmin_Rte_NvmBlock_PullCmpActv_PullCmpLongTerm}
        {enable-take-address=true, indirect-api=false, port-defined-argument-value{value=PAdmin_Rte_NvmBlock_SnsrOffsLrng_SnsrOffsLrnd_0:68, value-type=NvM_BlockIdType}, port=PAdmin_Rte_NvmBlock_SnsrOffsLrng_SnsrOffsLrnd}
        {enable-take-address=true, indirect-api=false, port-defined-argument-value{value=PS_CurrMeasMotEol_Deprecated_0:2, value-type=NvM_BlockIdType}, port=PS_CurrMeasMotEol_Deprecated}
        {enable-take-address=true, indirect-api=false, port-defined-argument-value{value=PS_Rte_NvmBlock_CDD_CurrMeas_CurrMeasEolGainCalSet_0:95, value-type=NvM_BlockIdType}, port=PS_Rte_NvmBlock_CDD_CurrMeas_CurrMeasEolGainCalSet}
        {enable-take-address=true, indirect-api=false, port-defined-argument-value{value=PS_Rte_NvmBlock_CDD_CurrMeas_CurrMeasEolOffsCalSet_0:96, value-type=NvM_BlockIdType}, port=PS_Rte_NvmBlock_CDD_CurrMeas_CurrMeasEolOffsCalSet}
        {enable-take-address=true, indirect-api=false, port-defined-argument-value{value=PS_Rte_NvmBlock_CDD_HwTq0Meas_HwTq0Offs_0:100, value-type=NvM_BlockIdType}, port=PS_Rte_NvmBlock_CDD_HwTq0Meas_HwTq0Offs}
        {enable-take-address=true, indirect-api=false, port-defined-argument-value{value=PS_Rte_NvmBlock_CDD_HwTq1Meas_HwTq1Offs_0:101, value-type=NvM_BlockIdType}, port=PS_Rte_NvmBlock_CDD_HwTq1Meas_HwTq1Offs}
        {enable-take-address=true, indirect-api=false, port-defined-argument-value{value=PS_Rte_NvmBlock_CDD_HwTq2Meas_HwTq2Offs_0:103, value-type=NvM_BlockIdType}, port=PS_Rte_NvmBlock_CDD_HwTq2Meas_HwTq2Offs}
        {enable-take-address=true, indirect-api=false, port-defined-argument-value{value=PS_Rte_NvmBlock_CDD_HwTq3Meas_HwTq3Offs_0:102, value-type=NvM_BlockIdType}, port=PS_Rte_NvmBlock_CDD_HwTq3Meas_HwTq3Offs}
        {enable-take-address=true, indirect-api=false, port-defined-argument-value{value=PS_Rte_NvmBlock_CDD_MotAgCmp_MotAgCmpMotAgBackEmf_0:113, value-type=NvM_BlockIdType}, port=PS_Rte_NvmBlock_CDD_MotAgCmp_MotAgCmpMotAgBackEmf}
        {enable-take-address=true, indirect-api=false, port-defined-argument-value{value=PS_Rte_NvmBlock_CmnMfgSrv_IgnCntr_0:111, value-type=NvM_BlockIdType}, port=PS_Rte_NvmBlock_CmnMfgSrv_IgnCntr}
        {enable-take-address=true, indirect-api=false, port-defined-argument-value{value=PS_Rte_NvmBlock_CmnMfgSrv_NxtrMfgEnaCntr_0:110, value-type=NvM_BlockIdType}, port=PS_Rte_NvmBlock_CmnMfgSrv_NxtrMfgEnaCntr}
        {enable-take-address=true, indirect-api=false, port-defined-argument-value{value=PS_Rte_NvmBlock_DiagcMgr_DiagcMgrNtcFltAry_0:98, value-type=NvM_BlockIdType}, port=PS_Rte_NvmBlock_DiagcMgr_DiagcMgrNtcFltAry}
        {enable-take-address=true, indirect-api=false, port-defined-argument-value{value=PS_Rte_NvmBlock_DutyCycThermProtn_FilStVal_0:71, value-type=NvM_BlockIdType}, port=PS_Rte_NvmBlock_DutyCycThermProtn_FilStVal}
        {enable-take-address=true, indirect-api=false, port-defined-argument-value{value=PS_Rte_NvmBlock_EotLrng_EotNvmData_0:97, value-type=NvM_BlockIdType}, port=PS_Rte_NvmBlock_EotLrng_EotNvmData}
        {enable-take-address=true, indirect-api=false, port-defined-argument-value{value=PS_Rte_NvmBlock_GmOvrlStMgr_GmLoaIgnCntr_0:67, value-type=NvM_BlockIdType}, port=PS_Rte_NvmBlock_GmOvrlStMgr_GmLoaIgnCntr}
        {enable-take-address=true, indirect-api=false, port-defined-argument-value{value=PS_Rte_NvmBlock_HwAg0Meas_HwAg0Offs_0:108, value-type=NvM_BlockIdType}, port=PS_Rte_NvmBlock_HwAg0Meas_HwAg0Offs}
        {enable-take-address=true, indirect-api=false, port-defined-argument-value{value=PS_Rte_NvmBlock_HwAg1Meas_HwAg1Offs_0:106, value-type=NvM_BlockIdType}, port=PS_Rte_NvmBlock_HwAg1Meas_HwAg1Offs}
        {enable-take-address=true, indirect-api=false, port-defined-argument-value{value=PS_Rte_NvmBlock_HwTqCorrln_HwTqChACmnModCmpLpFilSt_0:104, value-type=NvM_BlockIdType}, port=PS_Rte_NvmBlock_HwTqCorrln_HwTqChACmnModCmpLpFilSt}
        {enable-take-address=true, indirect-api=false, port-defined-argument-value{value=PS_Rte_NvmBlock_HwTqCorrln_HwTqChBCmnModCmpLpFilSt_0:105, value-type=NvM_BlockIdType}, port=PS_Rte_NvmBlock_HwTqCorrln_HwTqChBCmnModCmpLpFilSt}
        {enable-take-address=true, indirect-api=false, port-defined-argument-value{value=PS_Rte_NvmBlock_MotAg2Meas_MotAg2EolPrm_0:99, value-type=NvM_BlockIdType}, port=PS_Rte_NvmBlock_MotAg2Meas_MotAg2EolPrm}
        {enable-take-address=true, indirect-api=false, port-defined-argument-value{value=PS_Rte_NvmBlock_NvMProxy_ShtdwnClsChk_0:107, value-type=NvM_BlockIdType}, port=PS_Rte_NvmBlock_NvMProxy_ShtdwnClsChk}
        {enable-take-address=true, indirect-api=false, port-defined-argument-value{value=PS_Rte_NvmBlock_PartNr_PartNrBasMdlPartNr_0:87, value-type=NvM_BlockIdType}, port=PS_Rte_NvmBlock_PartNr_PartNrBasMdlPartNr}
        {enable-take-address=true, indirect-api=false, port-defined-argument-value{value=PS_Rte_NvmBlock_PartNr_PartNrCalProgdSts_0:92, value-type=NvM_BlockIdType}, port=PS_Rte_NvmBlock_PartNr_PartNrCalProgdSts}
        {enable-take-address=true, indirect-api=false, port-defined-argument-value{value=PS_Rte_NvmBlock_PartNr_PartNrCcaMfgTrakg_0:83, value-type=NvM_BlockIdType}, port=PS_Rte_NvmBlock_PartNr_PartNrCcaMfgTrakg}
        {enable-take-address=true, indirect-api=false, port-defined-argument-value{value=PS_Rte_NvmBlock_PartNr_PartNrCtrlPidSeedKey_0:88, value-type=NvM_BlockIdType}, port=PS_Rte_NvmBlock_PartNr_PartNrCtrlPidSeedKey}
        {enable-take-address=true, indirect-api=false, port-defined-argument-value{value=PS_Rte_NvmBlock_PartNr_PartNrCustMfgEnaCntr_0:93, value-type=NvM_BlockIdType}, port=PS_Rte_NvmBlock_PartNr_PartNrCustMfgEnaCntr}
        {enable-take-address=true, indirect-api=false, port-defined-argument-value{value=PS_Rte_NvmBlock_PartNr_PartNrDataUniversalNrSysId_0:91, value-type=NvM_BlockIdType}, port=PS_Rte_NvmBlock_PartNr_PartNrDataUniversalNrSysId}
        {enable-take-address=true, indirect-api=false, port-defined-argument-value{value=PS_Rte_NvmBlock_PartNr_PartNrEndMdlPartNr_0:86, value-type=NvM_BlockIdType}, port=PS_Rte_NvmBlock_PartNr_PartNrEndMdlPartNr}
        {enable-take-address=true, indirect-api=false, port-defined-argument-value{value=PS_Rte_NvmBlock_PartNr_PartNrNxtrMfgTrakg_0:85, value-type=NvM_BlockIdType}, port=PS_Rte_NvmBlock_PartNr_PartNrNxtrMfgTrakg}
        {enable-take-address=true, indirect-api=false, port-defined-argument-value{value=PS_Rte_NvmBlock_PartNr_PartNrProgmDate_0:90, value-type=NvM_BlockIdType}, port=PS_Rte_NvmBlock_PartNr_PartNrProgmDate}
        {enable-take-address=true, indirect-api=false, port-defined-argument-value{value=PS_Rte_NvmBlock_PartNr_PartNrProgmSessionSeedKey_0:94, value-type=NvM_BlockIdType}, port=PS_Rte_NvmBlock_PartNr_PartNrProgmSessionSeedKey}
        {enable-take-address=true, indirect-api=false, port-defined-argument-value{value=PS_Rte_NvmBlock_PartNr_PartNrRepairShopCod_0:81, value-type=NvM_BlockIdType}, port=PS_Rte_NvmBlock_PartNr_PartNrRepairShopCod}
        {enable-take-address=true, indirect-api=false, port-defined-argument-value{value=PS_Rte_NvmBlock_PartNr_PartNrSysCodVersNr_0:84, value-type=NvM_BlockIdType}, port=PS_Rte_NvmBlock_PartNr_PartNrSysCodVersNr}
        {enable-take-address=true, indirect-api=false, port-defined-argument-value{value=PS_Rte_NvmBlock_PartNr_PartNrSysName_0:82, value-type=NvM_BlockIdType}, port=PS_Rte_NvmBlock_PartNr_PartNrSysName}
        {enable-take-address=true, indirect-api=false, port-defined-argument-value{value=PS_Rte_NvmBlock_PartNr_PartNrVinData_0:89, value-type=NvM_BlockIdType}, port=PS_Rte_NvmBlock_PartNr_PartNrVinData}
        {enable-take-address=true, indirect-api=false, port-defined-argument-value{value=PS_Rte_NvmBlock_PullCmpActv_PullCmpLongTerm_0:70, value-type=NvM_BlockIdType}, port=PS_Rte_NvmBlock_PullCmpActv_PullCmpLongTerm}
        {enable-take-address=true, indirect-api=false, port-defined-argument-value{value=PS_Rte_NvmBlock_SnsrOffsLrng_SnsrOffsLrnd_0:68, value-type=NvM_BlockIdType}, port=PS_Rte_NvmBlock_SnsrOffsLrng_SnsrOffsLrnd}
      9 x runnable:
        EraseBlock: can-be-invoked-concurrently=true, symbol=NvM_EraseNvBlock
        GetErrorStatus: can-be-invoked-concurrently=true, symbol=NvM_GetErrorStatus
        InvalidateNvBlock: can-be-invoked-concurrently=true, symbol=NvM_InvalidateNvBlock
        NvM_MainFunction
        ReadBlock: can-be-invoked-concurrently=true, symbol=NvM_ReadBlock
        RestoreBlockDefaults: can-be-invoked-concurrently=true, symbol=NvM_RestoreBlockDefaults
        SetBlockProtection: can-be-invoked-concurrently=true, symbol=NvM_SetBlockProtection
        SetRamBlockStatus: can-be-invoked-concurrently=true, symbol=NvM_SetRamBlockStatus
        WriteBlock: can-be-invoked-concurrently=true, symbol=NvM_WriteBlock
  swc implementation NvMImplementation: behavior=NvMInternalBehavior
    code-descriptors:
      code Default: artifact-descriptors=autosar-engineering-object={short-label=Default, category=SWSRC}
